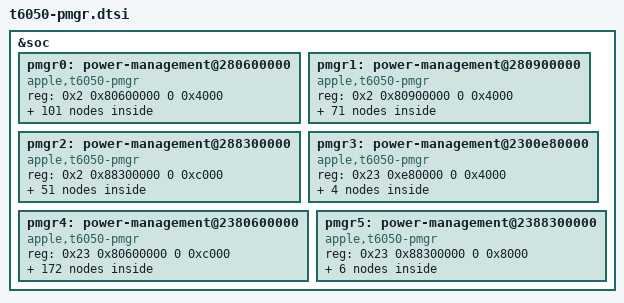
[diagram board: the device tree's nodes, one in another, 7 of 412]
// SPDX-License-Identifier: GPL-2.0+ OR MIT
/*
 * PMGR power domains for the Apple T6050 "M5 Pro" SoC
 *
 * GENERATED from the on-device ADT by scripts/adt2pmgr.py — do not edit
 * by hand; regenerate when the ADT changes (macOS updates can revise it).
 *
 * Copyright The Asahi Linux Contributors / omarchy-m5 contributors
 */

&soc {
	pmgr0: power-management@280600000 {
		compatible = "apple,t6050-pmgr", "apple,t8103-pmgr", "syscon", "simple-mfd";
		#address-cells = <1>;
		#size-cells = <1>;

		reg = <0x2 0x80600000 0 0x4000>;
	};

	pmgr1: power-management@280900000 {
		compatible = "apple,t6050-pmgr", "apple,t8103-pmgr", "syscon", "simple-mfd";
		#address-cells = <1>;
		#size-cells = <1>;

		reg = <0x2 0x80900000 0 0x4000>;
	};

	pmgr2: power-management@288300000 {
		compatible = "apple,t6050-pmgr", "apple,t8103-pmgr", "syscon", "simple-mfd";
		#address-cells = <1>;
		#size-cells = <1>;

		reg = <0x2 0x88300000 0 0xc000>;
	};

	pmgr3: power-management@2300e80000 {
		compatible = "apple,t6050-pmgr", "apple,t8103-pmgr", "syscon", "simple-mfd";
		#address-cells = <1>;
		#size-cells = <1>;

		reg = <0x23 0xe80000 0 0x4000>;
	};

	pmgr4: power-management@2380600000 {
		compatible = "apple,t6050-pmgr", "apple,t8103-pmgr", "syscon", "simple-mfd";
		#address-cells = <1>;
		#size-cells = <1>;

		reg = <0x23 0x80600000 0 0xc000>;
	};

	pmgr5: power-management@2388300000 {
		compatible = "apple,t6050-pmgr", "apple,t8103-pmgr", "syscon", "simple-mfd";
		#address-cells = <1>;
		#size-cells = <1>;

		reg = <0x23 0x88300000 0 0x8000>;
	};

};

&pmgr0 {

	ps_mcpu0_0: power-controller@0 {
		compatible = "apple,t6050-pmgr-pwrstate", "apple,t8103-pmgr-pwrstate";
		reg = <0x0 4>;
		#power-domain-cells = <0>;
		#reset-cells = <0>;
		label = "mcpu0_0";
	};

	ps_mcpu0_1: power-controller@8 {
		compatible = "apple,t6050-pmgr-pwrstate", "apple,t8103-pmgr-pwrstate";
		reg = <0x8 4>;
		#power-domain-cells = <0>;
		#reset-cells = <0>;
		label = "mcpu0_1";
	};

	ps_mcpu0_2: power-controller@10 {
		compatible = "apple,t6050-pmgr-pwrstate", "apple,t8103-pmgr-pwrstate";
		reg = <0x10 4>;
		#power-domain-cells = <0>;
		#reset-cells = <0>;
		label = "mcpu0_2";
	};

	ps_mcpu0_3: power-controller@18 {
		compatible = "apple,t6050-pmgr-pwrstate", "apple,t8103-pmgr-pwrstate";
		reg = <0x18 4>;
		#power-domain-cells = <0>;
		#reset-cells = <0>;
		label = "mcpu0_3";
	};

	ps_mcpu0_4: power-controller@20 {
		compatible = "apple,t6050-pmgr-pwrstate", "apple,t8103-pmgr-pwrstate";
		reg = <0x20 4>;
		#power-domain-cells = <0>;
		#reset-cells = <0>;
		label = "mcpu0_4";
	};

	ps_mcpu0_5: power-controller@28 {
		compatible = "apple,t6050-pmgr-pwrstate", "apple,t8103-pmgr-pwrstate";
		reg = <0x28 4>;
		#power-domain-cells = <0>;
		#reset-cells = <0>;
		label = "mcpu0_5";
	};

	ps_mcpu1_0: power-controller@30 {
		compatible = "apple,t6050-pmgr-pwrstate", "apple,t8103-pmgr-pwrstate";
		reg = <0x30 4>;
		#power-domain-cells = <0>;
		#reset-cells = <0>;
		label = "mcpu1_0";
	};

	ps_mcpu1_1: power-controller@38 {
		compatible = "apple,t6050-pmgr-pwrstate", "apple,t8103-pmgr-pwrstate";
		reg = <0x38 4>;
		#power-domain-cells = <0>;
		#reset-cells = <0>;
		label = "mcpu1_1";
	};

	ps_mcpu1_2: power-controller@40 {
		compatible = "apple,t6050-pmgr-pwrstate", "apple,t8103-pmgr-pwrstate";
		reg = <0x40 4>;
		#power-domain-cells = <0>;
		#reset-cells = <0>;
		label = "mcpu1_2";
	};

	ps_mcpu1_3: power-controller@48 {
		compatible = "apple,t6050-pmgr-pwrstate", "apple,t8103-pmgr-pwrstate";
		reg = <0x48 4>;
		#power-domain-cells = <0>;
		#reset-cells = <0>;
		label = "mcpu1_3";
	};

	ps_mcpu1_4: power-controller@50 {
		compatible = "apple,t6050-pmgr-pwrstate", "apple,t8103-pmgr-pwrstate";
		reg = <0x50 4>;
		#power-domain-cells = <0>;
		#reset-cells = <0>;
		label = "mcpu1_4";
	};

	ps_mcpu1_5: power-controller@58 {
		compatible = "apple,t6050-pmgr-pwrstate", "apple,t8103-pmgr-pwrstate";
		reg = <0x58 4>;
		#power-domain-cells = <0>;
		#reset-cells = <0>;
		label = "mcpu1_5";
	};

	ps_pcpu_0: power-controller@60 {
		compatible = "apple,t6050-pmgr-pwrstate", "apple,t8103-pmgr-pwrstate";
		reg = <0x60 4>;
		#power-domain-cells = <0>;
		#reset-cells = <0>;
		label = "pcpu_0";
	};

	ps_pcpu_1: power-controller@68 {
		compatible = "apple,t6050-pmgr-pwrstate", "apple,t8103-pmgr-pwrstate";
		reg = <0x68 4>;
		#power-domain-cells = <0>;
		#reset-cells = <0>;
		label = "pcpu_1";
	};

	ps_pcpu_2: power-controller@70 {
		compatible = "apple,t6050-pmgr-pwrstate", "apple,t8103-pmgr-pwrstate";
		reg = <0x70 4>;
		#power-domain-cells = <0>;
		#reset-cells = <0>;
		label = "pcpu_2";
	};

	ps_pcpu_3: power-controller@78 {
		compatible = "apple,t6050-pmgr-pwrstate", "apple,t8103-pmgr-pwrstate";
		reg = <0x78 4>;
		#power-domain-cells = <0>;
		#reset-cells = <0>;
		label = "pcpu_3";
	};

	ps_pcpu_4: power-controller@80 {
		compatible = "apple,t6050-pmgr-pwrstate", "apple,t8103-pmgr-pwrstate";
		reg = <0x80 4>;
		#power-domain-cells = <0>;
		#reset-cells = <0>;
		label = "pcpu_4";
	};

	ps_pcpu_5: power-controller@88 {
		compatible = "apple,t6050-pmgr-pwrstate", "apple,t8103-pmgr-pwrstate";
		reg = <0x88 4>;
		#power-domain-cells = <0>;
		#reset-cells = <0>;
		label = "pcpu_5";
	};

	ps_pms: power-controller@100 {
		compatible = "apple,t6050-pmgr-pwrstate", "apple,t8103-pmgr-pwrstate";
		reg = <0x100 4>;
		#power-domain-cells = <0>;
		#reset-cells = <0>;
		label = "pms";
		apple,always-on;
	};

	ps_aic: power-controller@108 {
		compatible = "apple,t6050-pmgr-pwrstate", "apple,t8103-pmgr-pwrstate";
		reg = <0x108 4>;
		#power-domain-cells = <0>;
		#reset-cells = <0>;
		label = "aic";
		power-domains = <&ps_pms>;
	};

	ps_pmc: power-controller@110 {
		compatible = "apple,t6050-pmgr-pwrstate", "apple,t8103-pmgr-pwrstate";
		reg = <0x110 4>;
		#power-domain-cells = <0>;
		#reset-cells = <0>;
		label = "pmc";
		apple,always-on;
		power-domains = <&ps_pms>;
	};

	ps_pms_c1ppt: power-controller@118 {
		compatible = "apple,t6050-pmgr-pwrstate", "apple,t8103-pmgr-pwrstate";
		reg = <0x118 4>;
		#power-domain-cells = <0>;
		#reset-cells = <0>;
		label = "pms_c1ppt";
		apple,always-on;
		power-domains = <&ps_pms>;
	};

	ps_soc_dpe: power-controller@120 {
		compatible = "apple,t6050-pmgr-pwrstate", "apple,t8103-pmgr-pwrstate";
		reg = <0x120 4>;
		#power-domain-cells = <0>;
		#reset-cells = <0>;
		label = "soc_dpe";
		apple,always-on;
		power-domains = <&ps_pms>;
	};

	ps_pmp: power-controller@128 {
		compatible = "apple,t6050-pmgr-pwrstate", "apple,t8103-pmgr-pwrstate";
		reg = <0x128 4>;
		#power-domain-cells = <0>;
		#reset-cells = <0>;
		label = "pmp";
		apple,always-on;
		power-domains = <&ps_pms>;
	};

	ps_pms_sram: power-controller@130 {
		compatible = "apple,t6050-pmgr-pwrstate", "apple,t8103-pmgr-pwrstate";
		reg = <0x130 4>;
		#power-domain-cells = <0>;
		#reset-cells = <0>;
		label = "pms_sram";
		apple,always-on;
		power-domains = <&ps_pms>;
	};

	ps_pmgr_soc_ocla: power-controller@138 {
		compatible = "apple,t6050-pmgr-pwrstate", "apple,t8103-pmgr-pwrstate";
		reg = <0x138 4>;
		#power-domain-cells = <0>;
		#reset-cells = <0>;
		label = "pmgr_soc_ocla";
	};

	ps_b2b_ctrl_nogate: power-controller@140 {
		compatible = "apple,t6050-pmgr-pwrstate", "apple,t8103-pmgr-pwrstate";
		reg = <0x140 4>;
		#power-domain-cells = <0>;
		#reset-cells = <0>;
		label = "b2b_ctrl_nogate";
		apple,always-on;
	};

	ps_fab0_acc_0: power-controller@148 {
		compatible = "apple,t6050-pmgr-pwrstate", "apple,t8103-pmgr-pwrstate";
		reg = <0x148 4>;
		#power-domain-cells = <0>;
		#reset-cells = <0>;
		label = "fab0_acc_0";
		apple,always-on;
	};

	ps_fab0_acc_1: power-controller@150 {
		compatible = "apple,t6050-pmgr-pwrstate", "apple,t8103-pmgr-pwrstate";
		reg = <0x150 4>;
		#power-domain-cells = <0>;
		#reset-cells = <0>;
		label = "fab0_acc_1";
		apple,always-on;
	};

	ps_fab2_acc: power-controller@158 {
		compatible = "apple,t6050-pmgr-pwrstate", "apple,t8103-pmgr-pwrstate";
		reg = <0x158 4>;
		#power-domain-cells = <0>;
		#reset-cells = <0>;
		label = "fab2_acc";
		apple,always-on;
	};

	ps_fab1_acc: power-controller@160 {
		compatible = "apple,t6050-pmgr-pwrstate", "apple,t8103-pmgr-pwrstate";
		reg = <0x160 4>;
		#power-domain-cells = <0>;
		#reset-cells = <0>;
		label = "fab1_acc";
		apple,always-on;
	};

	ps_b2bc_afc_0: power-controller@168 {
		compatible = "apple,t6050-pmgr-pwrstate", "apple,t8103-pmgr-pwrstate";
		reg = <0x168 4>;
		#power-domain-cells = <0>;
		#reset-cells = <0>;
		label = "b2bc_afc_0";
		apple,always-on;
	};

	ps_b2bc_afc_0_dfx: power-controller@170 {
		compatible = "apple,t6050-pmgr-pwrstate", "apple,t8103-pmgr-pwrstate";
		reg = <0x170 4>;
		#power-domain-cells = <0>;
		#reset-cells = <0>;
		label = "b2bc_afc_0_dfx";
		apple,always-on;
		power-domains = <&ps_b2bc_afc_0>;
	};

	ps_b2bc_afc_1: power-controller@178 {
		compatible = "apple,t6050-pmgr-pwrstate", "apple,t8103-pmgr-pwrstate";
		reg = <0x178 4>;
		#power-domain-cells = <0>;
		#reset-cells = <0>;
		label = "b2bc_afc_1";
		apple,always-on;
	};

	ps_b2bc_afc_1_dfx: power-controller@180 {
		compatible = "apple,t6050-pmgr-pwrstate", "apple,t8103-pmgr-pwrstate";
		reg = <0x180 4>;
		#power-domain-cells = <0>;
		#reset-cells = <0>;
		label = "b2bc_afc_1_dfx";
		apple,always-on;
		power-domains = <&ps_b2bc_afc_1>;
	};

	ps_fab0_afi_0: power-controller@188 {
		compatible = "apple,t6050-pmgr-pwrstate", "apple,t8103-pmgr-pwrstate";
		reg = <0x188 4>;
		#power-domain-cells = <0>;
		#reset-cells = <0>;
		label = "fab0_afi_0";
		apple,always-on;
	};

	ps_fab0_afi_1: power-controller@190 {
		compatible = "apple,t6050-pmgr-pwrstate", "apple,t8103-pmgr-pwrstate";
		reg = <0x190 4>;
		#power-domain-cells = <0>;
		#reset-cells = <0>;
		label = "fab0_afi_1";
		apple,always-on;
	};

	ps_fab0_afi_2: power-controller@198 {
		compatible = "apple,t6050-pmgr-pwrstate", "apple,t8103-pmgr-pwrstate";
		reg = <0x198 4>;
		#power-domain-cells = <0>;
		#reset-cells = <0>;
		label = "fab0_afi_2";
		apple,always-on;
	};

	ps_fab0_afi_3: power-controller@1a0 {
		compatible = "apple,t6050-pmgr-pwrstate", "apple,t8103-pmgr-pwrstate";
		reg = <0x1a0 4>;
		#power-domain-cells = <0>;
		#reset-cells = <0>;
		label = "fab0_afi_3";
		apple,always-on;
	};

	ps_fab_b2bc_afi_0: power-controller@1a8 {
		compatible = "apple,t6050-pmgr-pwrstate", "apple,t8103-pmgr-pwrstate";
		reg = <0x1a8 4>;
		#power-domain-cells = <0>;
		#reset-cells = <0>;
		label = "fab_b2bc_afi_0";
		apple,always-on;
	};

	ps_fab_b2bc_afi_1: power-controller@1b0 {
		compatible = "apple,t6050-pmgr-pwrstate", "apple,t8103-pmgr-pwrstate";
		reg = <0x1b0 4>;
		#power-domain-cells = <0>;
		#reset-cells = <0>;
		label = "fab_b2bc_afi_1";
		apple,always-on;
	};

	ps_b2bc_afi_0: power-controller@1b8 {
		compatible = "apple,t6050-pmgr-pwrstate", "apple,t8103-pmgr-pwrstate";
		reg = <0x1b8 4>;
		#power-domain-cells = <0>;
		#reset-cells = <0>;
		label = "b2bc_afi_0";
		apple,always-on;
	};

	ps_b2bc_afi_0_dfx: power-controller@1c0 {
		compatible = "apple,t6050-pmgr-pwrstate", "apple,t8103-pmgr-pwrstate";
		reg = <0x1c0 4>;
		#power-domain-cells = <0>;
		#reset-cells = <0>;
		label = "b2bc_afi_0_dfx";
		apple,always-on;
		power-domains = <&ps_b2bc_afi_0>;
	};

	ps_b2bc_afi_1: power-controller@1c8 {
		compatible = "apple,t6050-pmgr-pwrstate", "apple,t8103-pmgr-pwrstate";
		reg = <0x1c8 4>;
		#power-domain-cells = <0>;
		#reset-cells = <0>;
		label = "b2bc_afi_1";
		apple,always-on;
	};

	ps_b2bc_afi_1_dfx: power-controller@1d0 {
		compatible = "apple,t6050-pmgr-pwrstate", "apple,t8103-pmgr-pwrstate";
		reg = <0x1d0 4>;
		#power-domain-cells = <0>;
		#reset-cells = <0>;
		label = "b2bc_afi_1_dfx";
		apple,always-on;
		power-domains = <&ps_b2bc_afi_1>;
	};

	ps_fab0_piogw: power-controller@1d8 {
		compatible = "apple,t6050-pmgr-pwrstate", "apple,t8103-pmgr-pwrstate";
		reg = <0x1d8 4>;
		#power-domain-cells = <0>;
		#reset-cells = <0>;
		label = "fab0_piogw";
		apple,always-on;
	};

	ps_fab3_soc: power-controller@1e0 {
		compatible = "apple,t6050-pmgr-pwrstate", "apple,t8103-pmgr-pwrstate";
		reg = <0x1e0 4>;
		#power-domain-cells = <0>;
		#reset-cells = <0>;
		label = "fab3_soc";
		apple,always-on;
		power-domains = <&ps_fab0_piogw>;
	};

	ps_fab4_soc: power-controller@1e8 {
		compatible = "apple,t6050-pmgr-pwrstate", "apple,t8103-pmgr-pwrstate";
		reg = <0x1e8 4>;
		#power-domain-cells = <0>;
		#reset-cells = <0>;
		label = "fab4_soc";
		apple,always-on;
		power-domains = <&ps_fab0_piogw>;
	};

	ps_fab5_soc: power-controller@1f0 {
		compatible = "apple,t6050-pmgr-pwrstate", "apple,t8103-pmgr-pwrstate";
		reg = <0x1f0 4>;
		#power-domain-cells = <0>;
		#reset-cells = <0>;
		label = "fab5_soc";
		apple,always-on;
		power-domains = <&ps_fab0_piogw>;
	};

	ps_sbr: power-controller@1f8 {
		compatible = "apple,t6050-pmgr-pwrstate", "apple,t8103-pmgr-pwrstate";
		reg = <0x1f8 4>;
		#power-domain-cells = <0>;
		#reset-cells = <0>;
		label = "sbr";
		apple,always-on;
		power-domains = <&ps_fab3_soc>;
	};

	ps_dispext0_sys: power-controller@200 {
		compatible = "apple,t6050-pmgr-pwrstate", "apple,t8103-pmgr-pwrstate";
		reg = <0x200 4>;
		#power-domain-cells = <0>;
		#reset-cells = <0>;
		label = "dispext0_sys";
		power-domains = <&ps_fab3_soc>;
	};

	ps_atc0_common: power-controller@208 {
		compatible = "apple,t6050-pmgr-pwrstate", "apple,t8103-pmgr-pwrstate";
		reg = <0x208 4>;
		#power-domain-cells = <0>;
		#reset-cells = <0>;
		label = "atc0_common";
		power-domains = <&ps_fab3_soc>;
	};

	ps_atc1_common: power-controller@210 {
		compatible = "apple,t6050-pmgr-pwrstate", "apple,t8103-pmgr-pwrstate";
		reg = <0x210 4>;
		#power-domain-cells = <0>;
		#reset-cells = <0>;
		label = "atc1_common";
		power-domains = <&ps_fab3_soc>;
	};

	ps_dispext2_sys: power-controller@220 {
		compatible = "apple,t6050-pmgr-pwrstate", "apple,t8103-pmgr-pwrstate";
		reg = <0x220 4>;
		#power-domain-cells = <0>;
		#reset-cells = <0>;
		label = "dispext2_sys";
		power-domains = <&ps_fab4_soc>;
	};

	ps_dispext3_sys: power-controller@228 {
		compatible = "apple,t6050-pmgr-pwrstate", "apple,t8103-pmgr-pwrstate";
		reg = <0x228 4>;
		#power-domain-cells = <0>;
		#reset-cells = <0>;
		label = "dispext3_sys";
		power-domains = <&ps_fab4_soc>;
	};

	ps_dispext1_sys: power-controller@230 {
		compatible = "apple,t6050-pmgr-pwrstate", "apple,t8103-pmgr-pwrstate";
		reg = <0x230 4>;
		#power-domain-cells = <0>;
		#reset-cells = <0>;
		label = "dispext1_sys";
		power-domains = <&ps_fab5_soc>;
	};

	ps_atc2_common: power-controller@238 {
		compatible = "apple,t6050-pmgr-pwrstate", "apple,t8103-pmgr-pwrstate";
		reg = <0x238 4>;
		#power-domain-cells = <0>;
		#reset-cells = <0>;
		label = "atc2_common";
		power-domains = <&ps_fab5_soc>;
	};

	ps_atc3_common: power-controller@240 {
		compatible = "apple,t6050-pmgr-pwrstate", "apple,t8103-pmgr-pwrstate";
		reg = <0x240 4>;
		#power-domain-cells = <0>;
		#reset-cells = <0>;
		label = "atc3_common";
		power-domains = <&ps_fab5_soc>;
	};

	ps_auss: power-controller@248 {
		compatible = "apple,t6050-pmgr-pwrstate", "apple,t8103-pmgr-pwrstate";
		reg = <0x248 4>;
		#power-domain-cells = <0>;
		#reset-cells = <0>;
		label = "auss";
		power-domains = <&ps_fab5_soc>;
	};

	ps_gpio: power-controller@250 {
		compatible = "apple,t6050-pmgr-pwrstate", "apple,t8103-pmgr-pwrstate";
		reg = <0x250 4>;
		#power-domain-cells = <0>;
		#reset-cells = <0>;
		label = "gpio";
		power-domains = <&ps_sbr>;
	};

	ps_msg: power-controller@258 {
		compatible = "apple,t6050-pmgr-pwrstate", "apple,t8103-pmgr-pwrstate";
		reg = <0x258 4>;
		#power-domain-cells = <0>;
		#reset-cells = <0>;
		label = "msg";
		power-domains = <&ps_sbr>;
	};

	ps_ap_tmm: power-controller@260 {
		compatible = "apple,t6050-pmgr-pwrstate", "apple,t8103-pmgr-pwrstate";
		reg = <0x260 4>;
		#power-domain-cells = <0>;
		#reset-cells = <0>;
		label = "ap_tmm";
		power-domains = <&ps_sbr>;
	};

	ps_dispext0_fe: power-controller@268 {
		compatible = "apple,t6050-pmgr-pwrstate", "apple,t8103-pmgr-pwrstate";
		reg = <0x268 4>;
		#power-domain-cells = <0>;
		#reset-cells = <0>;
		label = "dispext0_fe";
		power-domains = <&ps_dispext0_sys>;
	};

	ps_dispext0_adma: power-controller@270 {
		compatible = "apple,t6050-pmgr-pwrstate", "apple,t8103-pmgr-pwrstate";
		reg = <0x270 4>;
		#power-domain-cells = <0>;
		#reset-cells = <0>;
		label = "dispext0_adma";
		power-domains = <&ps_dispext0_sys>;
	};

	ps_dispext0_cpu: power-controller@278 {
		compatible = "apple,t6050-pmgr-pwrstate", "apple,t8103-pmgr-pwrstate";
		reg = <0x278 4>;
		#power-domain-cells = <0>;
		#reset-cells = <0>;
		label = "dispext0_cpu";
		power-domains = <&ps_dispext0_fe>;
	};

	ps_atc0_cio: power-controller@280 {
		compatible = "apple,t6050-pmgr-pwrstate", "apple,t8103-pmgr-pwrstate";
		reg = <0x280 4>;
		#power-domain-cells = <0>;
		#reset-cells = <0>;
		label = "atc0_cio";
		power-domains = <&ps_atc0_common>;
	};

	ps_atc0_pcie: power-controller@288 {
		compatible = "apple,t6050-pmgr-pwrstate", "apple,t8103-pmgr-pwrstate";
		reg = <0x288 4>;
		#power-domain-cells = <0>;
		#reset-cells = <0>;
		label = "atc0_pcie";
		power-domains = <&ps_atc0_common>;
	};

	ps_atc1_cio: power-controller@290 {
		compatible = "apple,t6050-pmgr-pwrstate", "apple,t8103-pmgr-pwrstate";
		reg = <0x290 4>;
		#power-domain-cells = <0>;
		#reset-cells = <0>;
		label = "atc1_cio";
		power-domains = <&ps_atc1_common>;
	};

	ps_atc1_pcie: power-controller@298 {
		compatible = "apple,t6050-pmgr-pwrstate", "apple,t8103-pmgr-pwrstate";
		reg = <0x298 4>;
		#power-domain-cells = <0>;
		#reset-cells = <0>;
		label = "atc1_pcie";
		power-domains = <&ps_atc1_common>;
	};

	ps_dispext2_fe: power-controller@2a0 {
		compatible = "apple,t6050-pmgr-pwrstate", "apple,t8103-pmgr-pwrstate";
		reg = <0x2a0 4>;
		#power-domain-cells = <0>;
		#reset-cells = <0>;
		label = "dispext2_fe";
		power-domains = <&ps_dispext2_sys>;
	};

	ps_dispext2_adma: power-controller@2a8 {
		compatible = "apple,t6050-pmgr-pwrstate", "apple,t8103-pmgr-pwrstate";
		reg = <0x2a8 4>;
		#power-domain-cells = <0>;
		#reset-cells = <0>;
		label = "dispext2_adma";
		power-domains = <&ps_dispext2_sys>;
	};

	ps_dispext2_cpu: power-controller@2b0 {
		compatible = "apple,t6050-pmgr-pwrstate", "apple,t8103-pmgr-pwrstate";
		reg = <0x2b0 4>;
		#power-domain-cells = <0>;
		#reset-cells = <0>;
		label = "dispext2_cpu";
		power-domains = <&ps_dispext2_fe>;
	};

	ps_dispext3_fe: power-controller@2b8 {
		compatible = "apple,t6050-pmgr-pwrstate", "apple,t8103-pmgr-pwrstate";
		reg = <0x2b8 4>;
		#power-domain-cells = <0>;
		#reset-cells = <0>;
		label = "dispext3_fe";
		power-domains = <&ps_dispext3_sys>;
	};

	ps_dispext3_adma: power-controller@2c0 {
		compatible = "apple,t6050-pmgr-pwrstate", "apple,t8103-pmgr-pwrstate";
		reg = <0x2c0 4>;
		#power-domain-cells = <0>;
		#reset-cells = <0>;
		label = "dispext3_adma";
		power-domains = <&ps_dispext3_sys>;
	};

	ps_dispext3_cpu: power-controller@2c8 {
		compatible = "apple,t6050-pmgr-pwrstate", "apple,t8103-pmgr-pwrstate";
		reg = <0x2c8 4>;
		#power-domain-cells = <0>;
		#reset-cells = <0>;
		label = "dispext3_cpu";
		power-domains = <&ps_dispext3_fe>;
	};

	ps_dispext1_fe: power-controller@2d0 {
		compatible = "apple,t6050-pmgr-pwrstate", "apple,t8103-pmgr-pwrstate";
		reg = <0x2d0 4>;
		#power-domain-cells = <0>;
		#reset-cells = <0>;
		label = "dispext1_fe";
		power-domains = <&ps_dispext1_sys>;
	};

	ps_dispext1_adma: power-controller@2d8 {
		compatible = "apple,t6050-pmgr-pwrstate", "apple,t8103-pmgr-pwrstate";
		reg = <0x2d8 4>;
		#power-domain-cells = <0>;
		#reset-cells = <0>;
		label = "dispext1_adma";
		power-domains = <&ps_dispext1_sys>;
	};

	ps_dispext1_cpu: power-controller@2e0 {
		compatible = "apple,t6050-pmgr-pwrstate", "apple,t8103-pmgr-pwrstate";
		reg = <0x2e0 4>;
		#power-domain-cells = <0>;
		#reset-cells = <0>;
		label = "dispext1_cpu";
		power-domains = <&ps_dispext1_fe>;
	};

	ps_atc2_cio: power-controller@2e8 {
		compatible = "apple,t6050-pmgr-pwrstate", "apple,t8103-pmgr-pwrstate";
		reg = <0x2e8 4>;
		#power-domain-cells = <0>;
		#reset-cells = <0>;
		label = "atc2_cio";
		power-domains = <&ps_atc2_common>;
	};

	ps_atc2_pcie: power-controller@2f0 {
		compatible = "apple,t6050-pmgr-pwrstate", "apple,t8103-pmgr-pwrstate";
		reg = <0x2f0 4>;
		#power-domain-cells = <0>;
		#reset-cells = <0>;
		label = "atc2_pcie";
		power-domains = <&ps_atc2_common>;
	};

	ps_atc3_cio: power-controller@2f8 {
		compatible = "apple,t6050-pmgr-pwrstate", "apple,t8103-pmgr-pwrstate";
		reg = <0x2f8 4>;
		#power-domain-cells = <0>;
		#reset-cells = <0>;
		label = "atc3_cio";
		power-domains = <&ps_atc3_common>;
	};

	ps_atc3_pcie: power-controller@300 {
		compatible = "apple,t6050-pmgr-pwrstate", "apple,t8103-pmgr-pwrstate";
		reg = <0x300 4>;
		#power-domain-cells = <0>;
		#reset-cells = <0>;
		label = "atc3_pcie";
		power-domains = <&ps_atc3_common>;
	};

	ps_atc0_cio_pcie: power-controller@338 {
		compatible = "apple,t6050-pmgr-pwrstate", "apple,t8103-pmgr-pwrstate";
		reg = <0x338 4>;
		#power-domain-cells = <0>;
		#reset-cells = <0>;
		label = "atc0_cio_pcie";
		power-domains = <&ps_atc0_cio>;
	};

	ps_atc0_cio_usb: power-controller@340 {
		compatible = "apple,t6050-pmgr-pwrstate", "apple,t8103-pmgr-pwrstate";
		reg = <0x340 4>;
		#power-domain-cells = <0>;
		#reset-cells = <0>;
		label = "atc0_cio_usb";
		power-domains = <&ps_atc0_cio>;
	};

	ps_atc0_cio_auss: power-controller@348 {
		compatible = "apple,t6050-pmgr-pwrstate", "apple,t8103-pmgr-pwrstate";
		reg = <0x348 4>;
		#power-domain-cells = <0>;
		#reset-cells = <0>;
		label = "atc0_cio_auss";
		power-domains = <&ps_atc0_cio>, <&ps_auss>;
	};

	ps_atc1_cio_pcie: power-controller@350 {
		compatible = "apple,t6050-pmgr-pwrstate", "apple,t8103-pmgr-pwrstate";
		reg = <0x350 4>;
		#power-domain-cells = <0>;
		#reset-cells = <0>;
		label = "atc1_cio_pcie";
		power-domains = <&ps_atc1_cio>;
	};

	ps_atc1_cio_usb: power-controller@358 {
		compatible = "apple,t6050-pmgr-pwrstate", "apple,t8103-pmgr-pwrstate";
		reg = <0x358 4>;
		#power-domain-cells = <0>;
		#reset-cells = <0>;
		label = "atc1_cio_usb";
		power-domains = <&ps_atc1_cio>;
	};

	ps_atc1_cio_auss: power-controller@360 {
		compatible = "apple,t6050-pmgr-pwrstate", "apple,t8103-pmgr-pwrstate";
		reg = <0x360 4>;
		#power-domain-cells = <0>;
		#reset-cells = <0>;
		label = "atc1_cio_auss";
		power-domains = <&ps_atc1_cio>, <&ps_auss>;
	};

	ps_atc2_cio_pcie: power-controller@3f8 {
		compatible = "apple,t6050-pmgr-pwrstate", "apple,t8103-pmgr-pwrstate";
		reg = <0x3f8 4>;
		#power-domain-cells = <0>;
		#reset-cells = <0>;
		label = "atc2_cio_pcie";
		power-domains = <&ps_atc2_cio>;
	};

	ps_atc2_cio_usb: power-controller@400 {
		compatible = "apple,t6050-pmgr-pwrstate", "apple,t8103-pmgr-pwrstate";
		reg = <0x400 4>;
		#power-domain-cells = <0>;
		#reset-cells = <0>;
		label = "atc2_cio_usb";
		power-domains = <&ps_atc2_cio>;
	};

	ps_atc2_cio_auss: power-controller@408 {
		compatible = "apple,t6050-pmgr-pwrstate", "apple,t8103-pmgr-pwrstate";
		reg = <0x408 4>;
		#power-domain-cells = <0>;
		#reset-cells = <0>;
		label = "atc2_cio_auss";
		power-domains = <&ps_atc2_cio>, <&ps_auss>;
	};

	ps_atc3_cio_pcie: power-controller@410 {
		compatible = "apple,t6050-pmgr-pwrstate", "apple,t8103-pmgr-pwrstate";
		reg = <0x410 4>;
		#power-domain-cells = <0>;
		#reset-cells = <0>;
		label = "atc3_cio_pcie";
		power-domains = <&ps_atc3_cio>;
	};

	ps_atc3_cio_usb: power-controller@418 {
		compatible = "apple,t6050-pmgr-pwrstate", "apple,t8103-pmgr-pwrstate";
		reg = <0x418 4>;
		#power-domain-cells = <0>;
		#reset-cells = <0>;
		label = "atc3_cio_usb";
		power-domains = <&ps_atc3_cio>;
	};

	ps_atc3_cio_auss: power-controller@420 {
		compatible = "apple,t6050-pmgr-pwrstate", "apple,t8103-pmgr-pwrstate";
		reg = <0x420 4>;
		#power-domain-cells = <0>;
		#reset-cells = <0>;
		label = "atc3_cio_auss";
		power-domains = <&ps_atc3_cio>, <&ps_auss>;
	};

	ps_fab0_afigw: power-controller@448 {
		compatible = "apple,t6050-pmgr-pwrstate", "apple,t8103-pmgr-pwrstate";
		reg = <0x448 4>;
		#power-domain-cells = <0>;
		#reset-cells = <0>;
		label = "fab0_afigw";
		apple,always-on;
	};

	ps_fppt: power-controller@450 {
		compatible = "apple,t6050-pmgr-pwrstate", "apple,t8103-pmgr-pwrstate";
		reg = <0x450 4>;
		#power-domain-cells = <0>;
		#reset-cells = <0>;
		label = "fppt";
		power-domains = <&ps_fab0_afigw>;
	};

	ps_b2bc_dft: power-controller@458 {
		compatible = "apple,t6050-pmgr-pwrstate", "apple,t8103-pmgr-pwrstate";
		reg = <0x458 4>;
		#power-domain-cells = <0>;
		#reset-cells = <0>;
		label = "b2bc_dft";
	};

	ps_b2bc_cntl_dfx: power-controller@460 {
		compatible = "apple,t6050-pmgr-pwrstate", "apple,t8103-pmgr-pwrstate";
		reg = <0x460 4>;
		#power-domain-cells = <0>;
		#reset-cells = <0>;
		label = "b2bc_cntl_dfx";
	};

	ps_b2bc_dbg_0: power-controller@468 {
		compatible = "apple,t6050-pmgr-pwrstate", "apple,t8103-pmgr-pwrstate";
		reg = <0x468 4>;
		#power-domain-cells = <0>;
		#reset-cells = <0>;
		label = "b2bc_dbg_0";
	};

	ps_b2bc_dbg_1: power-controller@470 {
		compatible = "apple,t6050-pmgr-pwrstate", "apple,t8103-pmgr-pwrstate";
		reg = <0x470 4>;
		#power-domain-cells = <0>;
		#reset-cells = <0>;
		label = "b2bc_dbg_1";
	};

	ps_b2bc_dbg_2: power-controller@478 {
		compatible = "apple,t6050-pmgr-pwrstate", "apple,t8103-pmgr-pwrstate";
		reg = <0x478 4>;
		#power-domain-cells = <0>;
		#reset-cells = <0>;
		label = "b2bc_dbg_2";
	};
};

&pmgr1 {

	ps_ispsens0: power-controller@100 {
		compatible = "apple,t6050-pmgr-pwrstate", "apple,t8103-pmgr-pwrstate";
		reg = <0x100 4>;
		#power-domain-cells = <0>;
		#reset-cells = <0>;
		label = "ispsens0";
	};

	ps_global_aux_hpd_0: power-controller@108 {
		compatible = "apple,t6050-pmgr-pwrstate", "apple,t8103-pmgr-pwrstate";
		reg = <0x108 4>;
		#power-domain-cells = <0>;
		#reset-cells = <0>;
		label = "global_aux_hpd_0";
	};

	ps_global_aux_hpd_1: power-controller@110 {
		compatible = "apple,t6050-pmgr-pwrstate", "apple,t8103-pmgr-pwrstate";
		reg = <0x110 4>;
		#power-domain-cells = <0>;
		#reset-cells = <0>;
		label = "global_aux_hpd_1";
	};

	ps_apcie_gp: power-controller@118 {
		compatible = "apple,t6050-pmgr-pwrstate", "apple,t8103-pmgr-pwrstate";
		reg = <0x118 4>;
		#power-domain-cells = <0>;
		#reset-cells = <0>;
		label = "apcie_gp";
	};

	ps_apcie_ge: power-controller@120 {
		compatible = "apple,t6050-pmgr-pwrstate", "apple,t8103-pmgr-pwrstate";
		reg = <0x120 4>;
		#power-domain-cells = <0>;
		#reset-cells = <0>;
		label = "apcie_ge";
	};

	ps_apcie_st0: power-controller@128 {
		compatible = "apple,t6050-pmgr-pwrstate", "apple,t8103-pmgr-pwrstate";
		reg = <0x128 4>;
		#power-domain-cells = <0>;
		#reset-cells = <0>;
		label = "apcie_st0";
	};

	ps_apcie_st1: power-controller@130 {
		compatible = "apple,t6050-pmgr-pwrstate", "apple,t8103-pmgr-pwrstate";
		reg = <0x130 4>;
		#power-domain-cells = <0>;
		#reset-cells = <0>;
		label = "apcie_st1";
	};

	ps_fab6_soc: power-controller@138 {
		compatible = "apple,t6050-pmgr-pwrstate", "apple,t8103-pmgr-pwrstate";
		reg = <0x138 4>;
		#power-domain-cells = <0>;
		#reset-cells = <0>;
		label = "fab6_soc";
		apple,always-on;
		power-domains = <&ps_fab0_piogw>;
	};

	ps_ans: power-controller@140 {
		compatible = "apple,t6050-pmgr-pwrstate", "apple,t8103-pmgr-pwrstate";
		reg = <0x140 4>;
		#power-domain-cells = <0>;
		#reset-cells = <0>;
		label = "ans";
		power-domains = <&ps_fab6_soc>;
	};

	ps_apcie_sys_gp: power-controller@148 {
		compatible = "apple,t6050-pmgr-pwrstate", "apple,t8103-pmgr-pwrstate";
		reg = <0x148 4>;
		#power-domain-cells = <0>;
		#reset-cells = <0>;
		label = "apcie_sys_gp";
		power-domains = <&ps_apcie_gp>, <&ps_fab6_soc>;
	};

	ps_apcie_sys_st0: power-controller@150 {
		compatible = "apple,t6050-pmgr-pwrstate", "apple,t8103-pmgr-pwrstate";
		reg = <0x150 4>;
		#power-domain-cells = <0>;
		#reset-cells = <0>;
		label = "apcie_sys_st0";
		power-domains = <&ps_apcie_st0>, <&ps_ans>;
	};

	ps_apcie_sys_st1: power-controller@158 {
		compatible = "apple,t6050-pmgr-pwrstate", "apple,t8103-pmgr-pwrstate";
		reg = <0x158 4>;
		#power-domain-cells = <0>;
		#reset-cells = <0>;
		label = "apcie_sys_st1";
		power-domains = <&ps_apcie_st1>, <&ps_ans>;
	};

	ps_apcie_sys_gp_oc: power-controller@160 {
		compatible = "apple,t6050-pmgr-pwrstate", "apple,t8103-pmgr-pwrstate";
		reg = <0x160 4>;
		#power-domain-cells = <0>;
		#reset-cells = <0>;
		label = "apcie_sys_gp_oc";
		power-domains = <&ps_apcie_sys_gp>;
	};

	ps_apcie_sys_st0_o: power-controller@168 {
		compatible = "apple,t6050-pmgr-pwrstate", "apple,t8103-pmgr-pwrstate";
		reg = <0x168 4>;
		#power-domain-cells = <0>;
		#reset-cells = <0>;
		label = "apcie_sys_st0_o";
		power-domains = <&ps_apcie_sys_st0>;
	};

	ps_apcie_sys_st1_o: power-controller@170 {
		compatible = "apple,t6050-pmgr-pwrstate", "apple,t8103-pmgr-pwrstate";
		reg = <0x170 4>;
		#power-domain-cells = <0>;
		#reset-cells = <0>;
		label = "apcie_sys_st1_o";
		power-domains = <&ps_apcie_sys_st1>;
	};

	ps_fab7_soc: power-controller@178 {
		compatible = "apple,t6050-pmgr-pwrstate", "apple,t8103-pmgr-pwrstate";
		reg = <0x178 4>;
		#power-domain-cells = <0>;
		#reset-cells = <0>;
		label = "fab7_soc";
		apple,always-on;
		power-domains = <&ps_fab0_piogw>;
	};

	ps_disp_sys: power-controller@180 {
		compatible = "apple,t6050-pmgr-pwrstate", "apple,t8103-pmgr-pwrstate";
		reg = <0x180 4>;
		#power-domain-cells = <0>;
		#reset-cells = <0>;
		label = "disp_sys";
		power-domains = <&ps_fab7_soc>;
	};

	ps_apcie_sys_ge: power-controller@188 {
		compatible = "apple,t6050-pmgr-pwrstate", "apple,t8103-pmgr-pwrstate";
		reg = <0x188 4>;
		#power-domain-cells = <0>;
		#reset-cells = <0>;
		label = "apcie_sys_ge";
		power-domains = <&ps_apcie_ge>, <&ps_fab6_soc>;
	};

	ps_scodec: power-controller@190 {
		compatible = "apple,t6050-pmgr-pwrstate", "apple,t8103-pmgr-pwrstate";
		reg = <0x190 4>;
		#power-domain-cells = <0>;
		#reset-cells = <0>;
		label = "scodec";
		power-domains = <&ps_fab7_soc>;
	};

	ps_disp_fe: power-controller@198 {
		compatible = "apple,t6050-pmgr-pwrstate", "apple,t8103-pmgr-pwrstate";
		reg = <0x198 4>;
		#power-domain-cells = <0>;
		#reset-cells = <0>;
		label = "disp_fe";
		power-domains = <&ps_disp_sys>;
	};

	ps_disp_adma: power-controller@1a0 {
		compatible = "apple,t6050-pmgr-pwrstate", "apple,t8103-pmgr-pwrstate";
		reg = <0x1a0 4>;
		#power-domain-cells = <0>;
		#reset-cells = <0>;
		label = "disp_adma";
		power-domains = <&ps_disp_sys>;
	};

	ps_disp_cpu: power-controller@1a8 {
		compatible = "apple,t6050-pmgr-pwrstate", "apple,t8103-pmgr-pwrstate";
		reg = <0x1a8 4>;
		#power-domain-cells = <0>;
		#reset-cells = <0>;
		label = "disp_cpu";
		power-domains = <&ps_disp_fe>;
	};

	ps_apcie_phy_sw: power-controller@1b0 {
		compatible = "apple,t6050-pmgr-pwrstate", "apple,t8103-pmgr-pwrstate";
		reg = <0x1b0 4>;
		#power-domain-cells = <0>;
		#reset-cells = <0>;
		label = "apcie_phy_sw";
		power-domains = <&ps_apcie_sys_gp>, <&ps_apcie_sys_ge>;
	};

	ps_apcie_sys_ge_ol: power-controller@1b8 {
		compatible = "apple,t6050-pmgr-pwrstate", "apple,t8103-pmgr-pwrstate";
		reg = <0x1b8 4>;
		#power-domain-cells = <0>;
		#reset-cells = <0>;
		label = "apcie_sys_ge_ol";
		power-domains = <&ps_apcie_sys_ge>;
	};

	ps_scodec_streaming: power-controller@1c0 {
		compatible = "apple,t6050-pmgr-pwrstate", "apple,t8103-pmgr-pwrstate";
		reg = <0x1c0 4>;
		#power-domain-cells = <0>;
		#reset-cells = <0>;
		label = "scodec_streaming";
		power-domains = <&ps_scodec>;
	};

	ps_aphy_st0_aus5_a: power-controller@240 {
		compatible = "apple,t6050-pmgr-pwrstate", "apple,t8103-pmgr-pwrstate";
		reg = <0x240 4>;
		#power-domain-cells = <0>;
		#reset-cells = <0>;
		label = "aphy_st0_aus5_a";
		power-domains = <&ps_apcie_phy_sw>;
	};

	ps_aphy_st1_aus5_a: power-controller@248 {
		compatible = "apple,t6050-pmgr-pwrstate", "apple,t8103-pmgr-pwrstate";
		reg = <0x248 4>;
		#power-domain-cells = <0>;
		#reset-cells = <0>;
		label = "aphy_st1_aus5_a";
		power-domains = <&ps_apcie_phy_sw>;
	};

	ps_aphy_ge_aus5_a: power-controller@250 {
		compatible = "apple,t6050-pmgr-pwrstate", "apple,t8103-pmgr-pwrstate";
		reg = <0x250 4>;
		#power-domain-cells = <0>;
		#reset-cells = <0>;
		label = "aphy_ge_aus5_a";
		power-domains = <&ps_apcie_phy_sw>;
	};

	ps_aphy_gp_aus5_a: power-controller@258 {
		compatible = "apple,t6050-pmgr-pwrstate", "apple,t8103-pmgr-pwrstate";
		reg = <0x258 4>;
		#power-domain-cells = <0>;
		#reset-cells = <0>;
		label = "aphy_gp_aus5_a";
		power-domains = <&ps_apcie_phy_sw>;
	};

	ps_aphy_st0_aus5: power-controller@268 {
		compatible = "apple,t6050-pmgr-pwrstate", "apple,t8103-pmgr-pwrstate";
		reg = <0x268 4>;
		#power-domain-cells = <0>;
		#reset-cells = <0>;
		label = "aphy_st0_aus5";
		power-domains = <&ps_aphy_st0_aus5_a>;
	};

	ps_aphy_st1_aus5: power-controller@270 {
		compatible = "apple,t6050-pmgr-pwrstate", "apple,t8103-pmgr-pwrstate";
		reg = <0x270 4>;
		#power-domain-cells = <0>;
		#reset-cells = <0>;
		label = "aphy_st1_aus5";
		power-domains = <&ps_aphy_st1_aus5_a>;
	};

	ps_aphy_ge_aus5: power-controller@278 {
		compatible = "apple,t6050-pmgr-pwrstate", "apple,t8103-pmgr-pwrstate";
		reg = <0x278 4>;
		#power-domain-cells = <0>;
		#reset-cells = <0>;
		label = "aphy_ge_aus5";
		power-domains = <&ps_aphy_ge_aus5_a>;
	};

	ps_aphy_gp_aus5: power-controller@280 {
		compatible = "apple,t6050-pmgr-pwrstate", "apple,t8103-pmgr-pwrstate";
		reg = <0x280 4>;
		#power-domain-cells = <0>;
		#reset-cells = <0>;
		label = "aphy_gp_aus5";
		power-domains = <&ps_aphy_gp_aus5_a>;
	};

	ps_fab8_soc: power-controller@288 {
		compatible = "apple,t6050-pmgr-pwrstate", "apple,t8103-pmgr-pwrstate";
		reg = <0x288 4>;
		#power-domain-cells = <0>;
		#reset-cells = <0>;
		label = "fab8_soc";
		apple,always-on;
		power-domains = <&ps_fab0_piogw>;
	};

	ps_sio: power-controller@290 {
		compatible = "apple,t6050-pmgr-pwrstate", "apple,t8103-pmgr-pwrstate";
		reg = <0x290 4>;
		#power-domain-cells = <0>;
		#reset-cells = <0>;
		label = "sio";
		apple,always-on;
		power-domains = <&ps_fab8_soc>;
	};

	ps_sep: power-controller@298 {
		compatible = "apple,t6050-pmgr-pwrstate", "apple,t8103-pmgr-pwrstate";
		reg = <0x298 4>;
		#power-domain-cells = <0>;
		#reset-cells = <0>;
		label = "sep";
		apple,always-on;
		power-domains = <&ps_fab8_soc>;
	};

	ps_sio_cpu: power-controller@2a0 {
		compatible = "apple,t6050-pmgr-pwrstate", "apple,t8103-pmgr-pwrstate";
		reg = <0x2a0 4>;
		#power-domain-cells = <0>;
		#reset-cells = <0>;
		label = "sio_cpu";
		apple,always-on;
		power-domains = <&ps_sio>;
	};

	ps_fpwm0: power-controller@2a8 {
		compatible = "apple,t6050-pmgr-pwrstate", "apple,t8103-pmgr-pwrstate";
		reg = <0x2a8 4>;
		#power-domain-cells = <0>;
		#reset-cells = <0>;
		label = "fpwm0";
		power-domains = <&ps_sio>;
	};

	ps_fpwm2: power-controller@2b8 {
		compatible = "apple,t6050-pmgr-pwrstate", "apple,t8103-pmgr-pwrstate";
		reg = <0x2b8 4>;
		#power-domain-cells = <0>;
		#reset-cells = <0>;
		label = "fpwm2";
		power-domains = <&ps_sio>;
	};

	ps_i2c0: power-controller@2c0 {
		compatible = "apple,t6050-pmgr-pwrstate", "apple,t8103-pmgr-pwrstate";
		reg = <0x2c0 4>;
		#power-domain-cells = <0>;
		#reset-cells = <0>;
		label = "i2c0";
		power-domains = <&ps_sio>;
	};

	ps_i2c1: power-controller@2c8 {
		compatible = "apple,t6050-pmgr-pwrstate", "apple,t8103-pmgr-pwrstate";
		reg = <0x2c8 4>;
		#power-domain-cells = <0>;
		#reset-cells = <0>;
		label = "i2c1";
		power-domains = <&ps_sio>;
	};

	ps_i2c2: power-controller@2d0 {
		compatible = "apple,t6050-pmgr-pwrstate", "apple,t8103-pmgr-pwrstate";
		reg = <0x2d0 4>;
		#power-domain-cells = <0>;
		#reset-cells = <0>;
		label = "i2c2";
		power-domains = <&ps_sio>;
	};

	ps_i2c3: power-controller@2d8 {
		compatible = "apple,t6050-pmgr-pwrstate", "apple,t8103-pmgr-pwrstate";
		reg = <0x2d8 4>;
		#power-domain-cells = <0>;
		#reset-cells = <0>;
		label = "i2c3";
		power-domains = <&ps_sio>;
	};

	ps_i2c4: power-controller@2e0 {
		compatible = "apple,t6050-pmgr-pwrstate", "apple,t8103-pmgr-pwrstate";
		reg = <0x2e0 4>;
		#power-domain-cells = <0>;
		#reset-cells = <0>;
		label = "i2c4";
		power-domains = <&ps_sio>;
	};

	ps_i2c5: power-controller@2e8 {
		compatible = "apple,t6050-pmgr-pwrstate", "apple,t8103-pmgr-pwrstate";
		reg = <0x2e8 4>;
		#power-domain-cells = <0>;
		#reset-cells = <0>;
		label = "i2c5";
		power-domains = <&ps_sio>;
	};

	ps_i2c6: power-controller@2f0 {
		compatible = "apple,t6050-pmgr-pwrstate", "apple,t8103-pmgr-pwrstate";
		reg = <0x2f0 4>;
		#power-domain-cells = <0>;
		#reset-cells = <0>;
		label = "i2c6";
		power-domains = <&ps_sio>;
	};

	ps_i2c7: power-controller@2f8 {
		compatible = "apple,t6050-pmgr-pwrstate", "apple,t8103-pmgr-pwrstate";
		reg = <0x2f8 4>;
		#power-domain-cells = <0>;
		#reset-cells = <0>;
		label = "i2c7";
		power-domains = <&ps_sio>;
	};

	ps_i2c8: power-controller@300 {
		compatible = "apple,t6050-pmgr-pwrstate", "apple,t8103-pmgr-pwrstate";
		reg = <0x300 4>;
		#power-domain-cells = <0>;
		#reset-cells = <0>;
		label = "i2c8";
		power-domains = <&ps_sio>;
	};

	ps_spi_p: power-controller@308 {
		compatible = "apple,t6050-pmgr-pwrstate", "apple,t8103-pmgr-pwrstate";
		reg = <0x308 4>;
		#power-domain-cells = <0>;
		#reset-cells = <0>;
		label = "spi_p";
		power-domains = <&ps_sio>;
	};

	ps_uart_p: power-controller@310 {
		compatible = "apple,t6050-pmgr-pwrstate", "apple,t8103-pmgr-pwrstate";
		reg = <0x310 4>;
		#power-domain-cells = <0>;
		#reset-cells = <0>;
		label = "uart_p";
		power-domains = <&ps_sio>;
	};

	ps_aes: power-controller@318 {
		compatible = "apple,t6050-pmgr-pwrstate", "apple,t8103-pmgr-pwrstate";
		reg = <0x318 4>;
		#power-domain-cells = <0>;
		#reset-cells = <0>;
		label = "aes";
		power-domains = <&ps_sio>;
	};

	ps_spi0: power-controller@320 {
		compatible = "apple,t6050-pmgr-pwrstate", "apple,t8103-pmgr-pwrstate";
		reg = <0x320 4>;
		#power-domain-cells = <0>;
		#reset-cells = <0>;
		label = "spi0";
		power-domains = <&ps_spi_p>;
	};

	ps_spi1: power-controller@328 {
		compatible = "apple,t6050-pmgr-pwrstate", "apple,t8103-pmgr-pwrstate";
		reg = <0x328 4>;
		#power-domain-cells = <0>;
		#reset-cells = <0>;
		label = "spi1";
		power-domains = <&ps_spi_p>;
	};

	ps_spi2: power-controller@330 {
		compatible = "apple,t6050-pmgr-pwrstate", "apple,t8103-pmgr-pwrstate";
		reg = <0x330 4>;
		#power-domain-cells = <0>;
		#reset-cells = <0>;
		label = "spi2";
		power-domains = <&ps_spi_p>;
	};

	ps_spi3: power-controller@338 {
		compatible = "apple,t6050-pmgr-pwrstate", "apple,t8103-pmgr-pwrstate";
		reg = <0x338 4>;
		#power-domain-cells = <0>;
		#reset-cells = <0>;
		label = "spi3";
		power-domains = <&ps_spi_p>;
	};

	ps_spi4: power-controller@340 {
		compatible = "apple,t6050-pmgr-pwrstate", "apple,t8103-pmgr-pwrstate";
		reg = <0x340 4>;
		#power-domain-cells = <0>;
		#reset-cells = <0>;
		label = "spi4";
		power-domains = <&ps_spi_p>;
	};

	ps_spi5: power-controller@348 {
		compatible = "apple,t6050-pmgr-pwrstate", "apple,t8103-pmgr-pwrstate";
		reg = <0x348 4>;
		#power-domain-cells = <0>;
		#reset-cells = <0>;
		label = "spi5";
		power-domains = <&ps_spi_p>;
	};

	ps_qspi: power-controller@350 {
		compatible = "apple,t6050-pmgr-pwrstate", "apple,t8103-pmgr-pwrstate";
		reg = <0x350 4>;
		#power-domain-cells = <0>;
		#reset-cells = <0>;
		label = "qspi";
		power-domains = <&ps_spi_p>;
	};

	ps_uart_n: power-controller@358 {
		compatible = "apple,t6050-pmgr-pwrstate", "apple,t8103-pmgr-pwrstate";
		reg = <0x358 4>;
		#power-domain-cells = <0>;
		#reset-cells = <0>;
		label = "uart_n";
		power-domains = <&ps_uart_p>;
	};

	ps_uart0: power-controller@360 {
		compatible = "apple,t6050-pmgr-pwrstate", "apple,t8103-pmgr-pwrstate";
		reg = <0x360 4>;
		#power-domain-cells = <0>;
		#reset-cells = <0>;
		label = "uart0";
		power-domains = <&ps_uart_p>;
	};

	ps_uart1: power-controller@368 {
		compatible = "apple,t6050-pmgr-pwrstate", "apple,t8103-pmgr-pwrstate";
		reg = <0x368 4>;
		#power-domain-cells = <0>;
		#reset-cells = <0>;
		label = "uart1";
		power-domains = <&ps_uart_p>;
	};

	ps_uart2: power-controller@370 {
		compatible = "apple,t6050-pmgr-pwrstate", "apple,t8103-pmgr-pwrstate";
		reg = <0x370 4>;
		#power-domain-cells = <0>;
		#reset-cells = <0>;
		label = "uart2";
		power-domains = <&ps_uart_p>;
	};

	ps_uart3: power-controller@378 {
		compatible = "apple,t6050-pmgr-pwrstate", "apple,t8103-pmgr-pwrstate";
		reg = <0x378 4>;
		#power-domain-cells = <0>;
		#reset-cells = <0>;
		label = "uart3";
		power-domains = <&ps_uart_p>;
	};

	ps_uart4: power-controller@380 {
		compatible = "apple,t6050-pmgr-pwrstate", "apple,t8103-pmgr-pwrstate";
		reg = <0x380 4>;
		#power-domain-cells = <0>;
		#reset-cells = <0>;
		label = "uart4";
		power-domains = <&ps_uart_p>;
	};

	ps_uart5: power-controller@388 {
		compatible = "apple,t6050-pmgr-pwrstate", "apple,t8103-pmgr-pwrstate";
		reg = <0x388 4>;
		#power-domain-cells = <0>;
		#reset-cells = <0>;
		label = "uart5";
		power-domains = <&ps_uart_p>;
	};

	ps_uart6: power-controller@390 {
		compatible = "apple,t6050-pmgr-pwrstate", "apple,t8103-pmgr-pwrstate";
		reg = <0x390 4>;
		#power-domain-cells = <0>;
		#reset-cells = <0>;
		label = "uart6";
		power-domains = <&ps_uart_p>;
	};

	ps_fab9_soc: power-controller@398 {
		compatible = "apple,t6050-pmgr-pwrstate", "apple,t8103-pmgr-pwrstate";
		reg = <0x398 4>;
		#power-domain-cells = <0>;
		#reset-cells = <0>;
		label = "fab9_soc";
		apple,always-on;
		power-domains = <&ps_fab0_piogw>;
	};

	ps_isp_sys: power-controller@3a0 {
		compatible = "apple,t6050-pmgr-pwrstate", "apple,t8103-pmgr-pwrstate";
		reg = <0x3a0 4>;
		#power-domain-cells = <0>;
		#reset-cells = <0>;
		label = "isp_sys";
		power-domains = <&ps_fab9_soc>;
	};

	ps_ane_mpm: power-controller@3c0 {
		compatible = "apple,t6050-pmgr-pwrstate", "apple,t8103-pmgr-pwrstate";
		reg = <0x3c0 4>;
		#power-domain-cells = <0>;
		#reset-cells = <0>;
		label = "ane_mpm";
	};

	ps_ane_cpu: power-controller@3c8 {
		compatible = "apple,t6050-pmgr-pwrstate", "apple,t8103-pmgr-pwrstate";
		reg = <0x3c8 4>;
		#power-domain-cells = <0>;
		#reset-cells = <0>;
		label = "ane_cpu";
	};

	ps_ane_tdbase: power-controller@3d0 {
		compatible = "apple,t6050-pmgr-pwrstate", "apple,t8103-pmgr-pwrstate";
		reg = <0x3d0 4>;
		#power-domain-cells = <0>;
		#reset-cells = <0>;
		label = "ane_tdbase";
	};
};

&pmgr2 {

	ps_debug_gated: power-controller@58 {
		compatible = "apple,t6050-pmgr-pwrstate", "apple,t8103-pmgr-pwrstate";
		reg = <0x58 4>;
		#power-domain-cells = <0>;
		#reset-cells = <0>;
		label = "debug_gated";
		apple,always-on;
	};

	ps_nub_spmi_a0: power-controller@60 {
		compatible = "apple,t6050-pmgr-pwrstate", "apple,t8103-pmgr-pwrstate";
		reg = <0x60 4>;
		#power-domain-cells = <0>;
		#reset-cells = <0>;
		label = "nub_spmi_a0";
		apple,always-on;
	};

	ps_nub_spmi_a1: power-controller@68 {
		compatible = "apple,t6050-pmgr-pwrstate", "apple,t8103-pmgr-pwrstate";
		reg = <0x68 4>;
		#power-domain-cells = <0>;
		#reset-cells = <0>;
		label = "nub_spmi_a1";
		apple,always-on;
	};

	ps_nub_spmi_a2: power-controller@70 {
		compatible = "apple,t6050-pmgr-pwrstate", "apple,t8103-pmgr-pwrstate";
		reg = <0x70 4>;
		#power-domain-cells = <0>;
		#reset-cells = <0>;
		label = "nub_spmi_a2";
		apple,always-on;
	};

	ps_nub_aon: power-controller@78 {
		compatible = "apple,t6050-pmgr-pwrstate", "apple,t8103-pmgr-pwrstate";
		reg = <0x78 4>;
		#power-domain-cells = <0>;
		#reset-cells = <0>;
		label = "nub_aon";
		apple,always-on;
	};

	ps_nub_dock_channel: power-controller@80 {
		compatible = "apple,t6050-pmgr-pwrstate", "apple,t8103-pmgr-pwrstate";
		reg = <0x80 4>;
		#power-domain-cells = <0>;
		#reset-cells = <0>;
		label = "nub_dock_channel";
		apple,always-on;
		power-domains = <&ps_nub_aon>;
	};

	ps_nub_gpio: power-controller@88 {
		compatible = "apple,t6050-pmgr-pwrstate", "apple,t8103-pmgr-pwrstate";
		reg = <0x88 4>;
		#power-domain-cells = <0>;
		#reset-cells = <0>;
		label = "nub_gpio";
		apple,always-on;
	};

	ps_atc0_common_dp_0: power-controller@98 {
		compatible = "apple,t6050-pmgr-pwrstate", "apple,t8103-pmgr-pwrstate";
		reg = <0x98 4>;
		#power-domain-cells = <0>;
		#reset-cells = <0>;
		label = "atc0_common_dp_0";
	};

	ps_atc0_common_dp_1: power-controller@a0 {
		compatible = "apple,t6050-pmgr-pwrstate", "apple,t8103-pmgr-pwrstate";
		reg = <0xa0 4>;
		#power-domain-cells = <0>;
		#reset-cells = <0>;
		label = "atc0_common_dp_1";
	};

	ps_atc0_common_dp_2: power-controller@a8 {
		compatible = "apple,t6050-pmgr-pwrstate", "apple,t8103-pmgr-pwrstate";
		reg = <0xa8 4>;
		#power-domain-cells = <0>;
		#reset-cells = <0>;
		label = "atc0_common_dp_2";
	};

	ps_atc0_common_dp_3: power-controller@b0 {
		compatible = "apple,t6050-pmgr-pwrstate", "apple,t8103-pmgr-pwrstate";
		reg = <0xb0 4>;
		#power-domain-cells = <0>;
		#reset-cells = <0>;
		label = "atc0_common_dp_3";
	};

	ps_atc1_common_dp_0: power-controller@b8 {
		compatible = "apple,t6050-pmgr-pwrstate", "apple,t8103-pmgr-pwrstate";
		reg = <0xb8 4>;
		#power-domain-cells = <0>;
		#reset-cells = <0>;
		label = "atc1_common_dp_0";
	};

	ps_atc1_common_dp_1: power-controller@c0 {
		compatible = "apple,t6050-pmgr-pwrstate", "apple,t8103-pmgr-pwrstate";
		reg = <0xc0 4>;
		#power-domain-cells = <0>;
		#reset-cells = <0>;
		label = "atc1_common_dp_1";
	};

	ps_atc1_common_dp_2: power-controller@c8 {
		compatible = "apple,t6050-pmgr-pwrstate", "apple,t8103-pmgr-pwrstate";
		reg = <0xc8 4>;
		#power-domain-cells = <0>;
		#reset-cells = <0>;
		label = "atc1_common_dp_2";
	};

	ps_atc1_common_dp_3: power-controller@d0 {
		compatible = "apple,t6050-pmgr-pwrstate", "apple,t8103-pmgr-pwrstate";
		reg = <0xd0 4>;
		#power-domain-cells = <0>;
		#reset-cells = <0>;
		label = "atc1_common_dp_3";
	};

	ps_atc2_common_dp_0: power-controller@d8 {
		compatible = "apple,t6050-pmgr-pwrstate", "apple,t8103-pmgr-pwrstate";
		reg = <0xd8 4>;
		#power-domain-cells = <0>;
		#reset-cells = <0>;
		label = "atc2_common_dp_0";
	};

	ps_atc2_common_dp_1: power-controller@e0 {
		compatible = "apple,t6050-pmgr-pwrstate", "apple,t8103-pmgr-pwrstate";
		reg = <0xe0 4>;
		#power-domain-cells = <0>;
		#reset-cells = <0>;
		label = "atc2_common_dp_1";
	};

	ps_atc2_common_dp_2: power-controller@e8 {
		compatible = "apple,t6050-pmgr-pwrstate", "apple,t8103-pmgr-pwrstate";
		reg = <0xe8 4>;
		#power-domain-cells = <0>;
		#reset-cells = <0>;
		label = "atc2_common_dp_2";
	};

	ps_atc2_common_dp_3: power-controller@f0 {
		compatible = "apple,t6050-pmgr-pwrstate", "apple,t8103-pmgr-pwrstate";
		reg = <0xf0 4>;
		#power-domain-cells = <0>;
		#reset-cells = <0>;
		label = "atc2_common_dp_3";
	};

	ps_atc3_common_dp_0: power-controller@f8 {
		compatible = "apple,t6050-pmgr-pwrstate", "apple,t8103-pmgr-pwrstate";
		reg = <0xf8 4>;
		#power-domain-cells = <0>;
		#reset-cells = <0>;
		label = "atc3_common_dp_0";
	};

	ps_atc3_common_dp_1: power-controller@100 {
		compatible = "apple,t6050-pmgr-pwrstate", "apple,t8103-pmgr-pwrstate";
		reg = <0x100 4>;
		#power-domain-cells = <0>;
		#reset-cells = <0>;
		label = "atc3_common_dp_1";
	};

	ps_atc3_common_dp_2: power-controller@108 {
		compatible = "apple,t6050-pmgr-pwrstate", "apple,t8103-pmgr-pwrstate";
		reg = <0x108 4>;
		#power-domain-cells = <0>;
		#reset-cells = <0>;
		label = "atc3_common_dp_2";
	};

	ps_atc3_common_dp_3: power-controller@110 {
		compatible = "apple,t6050-pmgr-pwrstate", "apple,t8103-pmgr-pwrstate";
		reg = <0x110 4>;
		#power-domain-cells = <0>;
		#reset-cells = <0>;
		label = "atc3_common_dp_3";
	};

	ps_nub_spmi_ahb: power-controller@118 {
		compatible = "apple,t6050-pmgr-pwrstate", "apple,t8103-pmgr-pwrstate";
		reg = <0x118 4>;
		#power-domain-cells = <0>;
		#reset-cells = <0>;
		label = "nub_spmi_ahb";
		apple,always-on;
	};

	ps_nub_spmi0: power-controller@120 {
		compatible = "apple,t6050-pmgr-pwrstate", "apple,t8103-pmgr-pwrstate";
		reg = <0x120 4>;
		#power-domain-cells = <0>;
		#reset-cells = <0>;
		label = "nub_spmi0";
		apple,always-on;
		power-domains = <&ps_nub_spmi_ahb>;
	};

	ps_nub_spmi1: power-controller@128 {
		compatible = "apple,t6050-pmgr-pwrstate", "apple,t8103-pmgr-pwrstate";
		reg = <0x128 4>;
		#power-domain-cells = <0>;
		#reset-cells = <0>;
		label = "nub_spmi1";
		apple,always-on;
		power-domains = <&ps_nub_spmi_ahb>;
	};

	ps_nub_spmi2: power-controller@130 {
		compatible = "apple,t6050-pmgr-pwrstate", "apple,t8103-pmgr-pwrstate";
		reg = <0x130 4>;
		#power-domain-cells = <0>;
		#reset-cells = <0>;
		label = "nub_spmi2";
		apple,always-on;
		power-domains = <&ps_nub_spmi_ahb>;
	};

	ps_nub_spmi3: power-controller@138 {
		compatible = "apple,t6050-pmgr-pwrstate", "apple,t8103-pmgr-pwrstate";
		reg = <0x138 4>;
		#power-domain-cells = <0>;
		#reset-cells = <0>;
		label = "nub_spmi3";
		apple,always-on;
		power-domains = <&ps_nub_spmi_ahb>;
	};

	ps_nub_spmi4: power-controller@140 {
		compatible = "apple,t6050-pmgr-pwrstate", "apple,t8103-pmgr-pwrstate";
		reg = <0x140 4>;
		#power-domain-cells = <0>;
		#reset-cells = <0>;
		label = "nub_spmi4";
		apple,always-on;
		power-domains = <&ps_nub_spmi_ahb>;
	};

	ps_atc0_usb_aon: power-controller@148 {
		compatible = "apple,t6050-pmgr-pwrstate", "apple,t8103-pmgr-pwrstate";
		reg = <0x148 4>;
		#power-domain-cells = <0>;
		#reset-cells = <0>;
		label = "atc0_usb_aon";
	};

	ps_atc0_usb: power-controller@150 {
		compatible = "apple,t6050-pmgr-pwrstate", "apple,t8103-pmgr-pwrstate";
		reg = <0x150 4>;
		#power-domain-cells = <0>;
		#reset-cells = <0>;
		label = "atc0_usb";
		power-domains = <&ps_atc0_common>, <&ps_atc0_usb_aon>;
	};

	ps_atc0_phymxwrap: power-controller@158 {
		compatible = "apple,t6050-pmgr-pwrstate", "apple,t8103-pmgr-pwrstate";
		reg = <0x158 4>;
		#power-domain-cells = <0>;
		#reset-cells = <0>;
		label = "atc0_phymxwrap";
		power-domains = <&ps_atc0_common>, <&ps_atc0_usb_aon>;
	};

	ps_atc1_usb_aon: power-controller@160 {
		compatible = "apple,t6050-pmgr-pwrstate", "apple,t8103-pmgr-pwrstate";
		reg = <0x160 4>;
		#power-domain-cells = <0>;
		#reset-cells = <0>;
		label = "atc1_usb_aon";
	};

	ps_atc1_usb: power-controller@168 {
		compatible = "apple,t6050-pmgr-pwrstate", "apple,t8103-pmgr-pwrstate";
		reg = <0x168 4>;
		#power-domain-cells = <0>;
		#reset-cells = <0>;
		label = "atc1_usb";
		power-domains = <&ps_atc1_common>, <&ps_atc1_usb_aon>;
	};

	ps_atc1_phymxwrap: power-controller@170 {
		compatible = "apple,t6050-pmgr-pwrstate", "apple,t8103-pmgr-pwrstate";
		reg = <0x170 4>;
		#power-domain-cells = <0>;
		#reset-cells = <0>;
		label = "atc1_phymxwrap";
		power-domains = <&ps_atc1_common>, <&ps_atc1_usb_aon>;
	};

	ps_atc2_usb_aon: power-controller@178 {
		compatible = "apple,t6050-pmgr-pwrstate", "apple,t8103-pmgr-pwrstate";
		reg = <0x178 4>;
		#power-domain-cells = <0>;
		#reset-cells = <0>;
		label = "atc2_usb_aon";
	};

	ps_atc2_usb: power-controller@180 {
		compatible = "apple,t6050-pmgr-pwrstate", "apple,t8103-pmgr-pwrstate";
		reg = <0x180 4>;
		#power-domain-cells = <0>;
		#reset-cells = <0>;
		label = "atc2_usb";
		power-domains = <&ps_atc2_common>, <&ps_atc2_usb_aon>;
	};

	ps_atc2_phymxwrap: power-controller@188 {
		compatible = "apple,t6050-pmgr-pwrstate", "apple,t8103-pmgr-pwrstate";
		reg = <0x188 4>;
		#power-domain-cells = <0>;
		#reset-cells = <0>;
		label = "atc2_phymxwrap";
		power-domains = <&ps_atc2_common>, <&ps_atc2_usb_aon>;
	};

	ps_atc3_usb_aon: power-controller@190 {
		compatible = "apple,t6050-pmgr-pwrstate", "apple,t8103-pmgr-pwrstate";
		reg = <0x190 4>;
		#power-domain-cells = <0>;
		#reset-cells = <0>;
		label = "atc3_usb_aon";
	};

	ps_atc3_usb: power-controller@198 {
		compatible = "apple,t6050-pmgr-pwrstate", "apple,t8103-pmgr-pwrstate";
		reg = <0x198 4>;
		#power-domain-cells = <0>;
		#reset-cells = <0>;
		label = "atc3_usb";
		power-domains = <&ps_atc3_common>, <&ps_atc3_usb_aon>;
	};

	ps_atc3_phymxwrap: power-controller@1a0 {
		compatible = "apple,t6050-pmgr-pwrstate", "apple,t8103-pmgr-pwrstate";
		reg = <0x1a0 4>;
		#power-domain-cells = <0>;
		#reset-cells = <0>;
		label = "atc3_phymxwrap";
		power-domains = <&ps_atc3_common>, <&ps_atc3_usb_aon>;
	};

	ps_nub_fabric: power-controller@1a8 {
		compatible = "apple,t6050-pmgr-pwrstate", "apple,t8103-pmgr-pwrstate";
		reg = <0x1a8 4>;
		#power-domain-cells = <0>;
		#reset-cells = <0>;
		label = "nub_fabric";
		apple,always-on;
	};

	ps_nub_sram: power-controller@1b0 {
		compatible = "apple,t6050-pmgr-pwrstate", "apple,t8103-pmgr-pwrstate";
		reg = <0x1b0 4>;
		#power-domain-cells = <0>;
		#reset-cells = <0>;
		label = "nub_sram";
		apple,always-on;
		power-domains = <&ps_nub_fabric>;
	};

	ps_debug_switch: power-controller@1b8 {
		compatible = "apple,t6050-pmgr-pwrstate", "apple,t8103-pmgr-pwrstate";
		reg = <0x1b8 4>;
		#power-domain-cells = <0>;
		#reset-cells = <0>;
		label = "debug_switch";
		apple,always-on;
	};

	ps_smc_i2cm0: power-controller@8028 {
		compatible = "apple,t6050-pmgr-pwrstate", "apple,t8103-pmgr-pwrstate";
		reg = <0x8028 4>;
		#power-domain-cells = <0>;
		#reset-cells = <0>;
		label = "smc_i2cm0";
	};

	ps_smc_i2cm1: power-controller@8030 {
		compatible = "apple,t6050-pmgr-pwrstate", "apple,t8103-pmgr-pwrstate";
		reg = <0x8030 4>;
		#power-domain-cells = <0>;
		#reset-cells = <0>;
		label = "smc_i2cm1";
	};

	ps_smc_i2cm2: power-controller@8038 {
		compatible = "apple,t6050-pmgr-pwrstate", "apple,t8103-pmgr-pwrstate";
		reg = <0x8038 4>;
		#power-domain-cells = <0>;
		#reset-cells = <0>;
		label = "smc_i2cm2";
	};

	ps_smc_i2cm3: power-controller@8040 {
		compatible = "apple,t6050-pmgr-pwrstate", "apple,t8103-pmgr-pwrstate";
		reg = <0x8040 4>;
		#power-domain-cells = <0>;
		#reset-cells = <0>;
		label = "smc_i2cm3";
	};

	ps_smc_i2cm4: power-controller@8048 {
		compatible = "apple,t6050-pmgr-pwrstate", "apple,t8103-pmgr-pwrstate";
		reg = <0x8048 4>;
		#power-domain-cells = <0>;
		#reset-cells = <0>;
		label = "smc_i2cm4";
	};

	ps_smc_i2cm5: power-controller@8050 {
		compatible = "apple,t6050-pmgr-pwrstate", "apple,t8103-pmgr-pwrstate";
		reg = <0x8050 4>;
		#power-domain-cells = <0>;
		#reset-cells = <0>;
		label = "smc_i2cm5";
	};

	ps_smc_i2cm6: power-controller@8058 {
		compatible = "apple,t6050-pmgr-pwrstate", "apple,t8103-pmgr-pwrstate";
		reg = <0x8058 4>;
		#power-domain-cells = <0>;
		#reset-cells = <0>;
		label = "smc_i2cm6";
	};
};

&pmgr3 {

	ps_gpx: power-controller@0 {
		compatible = "apple,t6050-pmgr-pwrstate", "apple,t8103-pmgr-pwrstate";
		reg = <0x0 4>;
		#power-domain-cells = <0>;
		#reset-cells = <0>;
		label = "gpx";
		apple,always-on;
	};

	ps_afr: power-controller@100 {
		compatible = "apple,t6050-pmgr-pwrstate", "apple,t8103-pmgr-pwrstate";
		reg = <0x100 4>;
		#power-domain-cells = <0>;
		#reset-cells = <0>;
		label = "afr";
		apple,always-on;
	};

	ps_cs: power-controller@108 {
		compatible = "apple,t6050-pmgr-pwrstate", "apple,t8103-pmgr-pwrstate";
		reg = <0x108 4>;
		#power-domain-cells = <0>;
		#reset-cells = <0>;
		label = "cs";
		power-domains = <&ps_afr>;
	};

	ps_gfx: power-controller@110 {
		compatible = "apple,t6050-pmgr-pwrstate", "apple,t8103-pmgr-pwrstate";
		reg = <0x110 4>;
		#power-domain-cells = <0>;
		#reset-cells = <0>;
		label = "gfx";
		power-domains = <&ps_afr>, <&ps_gpx>;
	};
};

&pmgr4 {

	ps_pms_gfx: power-controller@100 {
		compatible = "apple,t6050-pmgr-pwrstate", "apple,t8103-pmgr-pwrstate";
		reg = <0x100 4>;
		#power-domain-cells = <0>;
		#reset-cells = <0>;
		label = "pms_gfx";
		apple,always-on;
	};

	ps_aic_gfx: power-controller@108 {
		compatible = "apple,t6050-pmgr-pwrstate", "apple,t8103-pmgr-pwrstate";
		reg = <0x108 4>;
		#power-domain-cells = <0>;
		#reset-cells = <0>;
		label = "aic_gfx";
		power-domains = <&ps_pms_gfx>;
	};

	ps_pms_gfx_c1ppt: power-controller@110 {
		compatible = "apple,t6050-pmgr-pwrstate", "apple,t8103-pmgr-pwrstate";
		reg = <0x110 4>;
		#power-domain-cells = <0>;
		#reset-cells = <0>;
		label = "pms_gfx_c1ppt";
		apple,always-on;
		power-domains = <&ps_pms_gfx>;
	};

	ps_soc_dpe_gfx: power-controller@118 {
		compatible = "apple,t6050-pmgr-pwrstate", "apple,t8103-pmgr-pwrstate";
		reg = <0x118 4>;
		#power-domain-cells = <0>;
		#reset-cells = <0>;
		label = "soc_dpe_gfx";
		apple,always-on;
		power-domains = <&ps_pms_gfx>;
	};

	ps_pmgr_soc_ocla_g: power-controller@120 {
		compatible = "apple,t6050-pmgr-pwrstate", "apple,t8103-pmgr-pwrstate";
		reg = <0x120 4>;
		#power-domain-cells = <0>;
		#reset-cells = <0>;
		label = "pmgr_soc_ocla_g";
	};

	ps_b2b_ctrl_gfx: power-controller@128 {
		compatible = "apple,t6050-pmgr-pwrstate", "apple,t8103-pmgr-pwrstate";
		reg = <0x128 4>;
		#power-domain-cells = <0>;
		#reset-cells = <0>;
		label = "b2b_ctrl_gfx";
	};

	ps_b2bg_afc_0: power-controller@130 {
		compatible = "apple,t6050-pmgr-pwrstate", "apple,t8103-pmgr-pwrstate";
		reg = <0x130 4>;
		#power-domain-cells = <0>;
		#reset-cells = <0>;
		label = "b2bg_afc_0";
		apple,always-on;
	};

	ps_b2bg_afc_0_dfx: power-controller@138 {
		compatible = "apple,t6050-pmgr-pwrstate", "apple,t8103-pmgr-pwrstate";
		reg = <0x138 4>;
		#power-domain-cells = <0>;
		#reset-cells = <0>;
		label = "b2bg_afc_0_dfx";
		apple,always-on;
		power-domains = <&ps_b2bg_afc_0>;
	};

	ps_b2bg_afc_1: power-controller@140 {
		compatible = "apple,t6050-pmgr-pwrstate", "apple,t8103-pmgr-pwrstate";
		reg = <0x140 4>;
		#power-domain-cells = <0>;
		#reset-cells = <0>;
		label = "b2bg_afc_1";
		apple,always-on;
	};

	ps_b2bg_afc_1_dfx: power-controller@148 {
		compatible = "apple,t6050-pmgr-pwrstate", "apple,t8103-pmgr-pwrstate";
		reg = <0x148 4>;
		#power-domain-cells = <0>;
		#reset-cells = <0>;
		label = "b2bg_afc_1_dfx";
		apple,always-on;
		power-domains = <&ps_b2bg_afc_1>;
	};

	ps_fab1_afi_0: power-controller@150 {
		compatible = "apple,t6050-pmgr-pwrstate", "apple,t8103-pmgr-pwrstate";
		reg = <0x150 4>;
		#power-domain-cells = <0>;
		#reset-cells = <0>;
		label = "fab1_afi_0";
		apple,always-on;
	};

	ps_fab1_afi_1: power-controller@158 {
		compatible = "apple,t6050-pmgr-pwrstate", "apple,t8103-pmgr-pwrstate";
		reg = <0x158 4>;
		#power-domain-cells = <0>;
		#reset-cells = <0>;
		label = "fab1_afi_1";
		apple,always-on;
	};

	ps_fab_b2bg_afi_0: power-controller@160 {
		compatible = "apple,t6050-pmgr-pwrstate", "apple,t8103-pmgr-pwrstate";
		reg = <0x160 4>;
		#power-domain-cells = <0>;
		#reset-cells = <0>;
		label = "fab_b2bg_afi_0";
		apple,always-on;
	};

	ps_fab_b2bg_afi_1: power-controller@168 {
		compatible = "apple,t6050-pmgr-pwrstate", "apple,t8103-pmgr-pwrstate";
		reg = <0x168 4>;
		#power-domain-cells = <0>;
		#reset-cells = <0>;
		label = "fab_b2bg_afi_1";
		apple,always-on;
	};

	ps_b2bg_afi_0: power-controller@170 {
		compatible = "apple,t6050-pmgr-pwrstate", "apple,t8103-pmgr-pwrstate";
		reg = <0x170 4>;
		#power-domain-cells = <0>;
		#reset-cells = <0>;
		label = "b2bg_afi_0";
		apple,always-on;
	};

	ps_b2bg_afi_0_dfx: power-controller@178 {
		compatible = "apple,t6050-pmgr-pwrstate", "apple,t8103-pmgr-pwrstate";
		reg = <0x178 4>;
		#power-domain-cells = <0>;
		#reset-cells = <0>;
		label = "b2bg_afi_0_dfx";
		apple,always-on;
		power-domains = <&ps_b2bg_afi_0>;
	};

	ps_b2bg_afi_1: power-controller@180 {
		compatible = "apple,t6050-pmgr-pwrstate", "apple,t8103-pmgr-pwrstate";
		reg = <0x180 4>;
		#power-domain-cells = <0>;
		#reset-cells = <0>;
		label = "b2bg_afi_1";
		apple,always-on;
	};

	ps_b2bg_afi_1_dfx: power-controller@188 {
		compatible = "apple,t6050-pmgr-pwrstate", "apple,t8103-pmgr-pwrstate";
		reg = <0x188 4>;
		#power-domain-cells = <0>;
		#reset-cells = <0>;
		label = "b2bg_afi_1_dfx";
		apple,always-on;
		power-domains = <&ps_b2bg_afi_1>;
	};

	ps_fab1_afigw: power-controller@190 {
		compatible = "apple,t6050-pmgr-pwrstate", "apple,t8103-pmgr-pwrstate";
		reg = <0x190 4>;
		#power-domain-cells = <0>;
		#reset-cells = <0>;
		label = "fab1_afigw";
		apple,always-on;
	};

	ps_fppt_gfx: power-controller@198 {
		compatible = "apple,t6050-pmgr-pwrstate", "apple,t8103-pmgr-pwrstate";
		reg = <0x198 4>;
		#power-domain-cells = <0>;
		#reset-cells = <0>;
		label = "fppt_gfx";
		power-domains = <&ps_fab1_afigw>;
	};

	ps_fab1_piogw: power-controller@1a0 {
		compatible = "apple,t6050-pmgr-pwrstate", "apple,t8103-pmgr-pwrstate";
		reg = <0x1a0 4>;
		#power-domain-cells = <0>;
		#reset-cells = <0>;
		label = "fab1_piogw";
		apple,always-on;
	};

	ps_fab0_soc: power-controller@1a8 {
		compatible = "apple,t6050-pmgr-pwrstate", "apple,t8103-pmgr-pwrstate";
		reg = <0x1a8 4>;
		#power-domain-cells = <0>;
		#reset-cells = <0>;
		label = "fab0_soc";
		apple,always-on;
		power-domains = <&ps_fab1_piogw>;
	};

	ps_fab1_soc: power-controller@1b0 {
		compatible = "apple,t6050-pmgr-pwrstate", "apple,t8103-pmgr-pwrstate";
		reg = <0x1b0 4>;
		#power-domain-cells = <0>;
		#reset-cells = <0>;
		label = "fab1_soc";
		apple,always-on;
		power-domains = <&ps_fab1_piogw>;
	};

	ps_fab2_soc: power-controller@1b8 {
		compatible = "apple,t6050-pmgr-pwrstate", "apple,t8103-pmgr-pwrstate";
		reg = <0x1b8 4>;
		#power-domain-cells = <0>;
		#reset-cells = <0>;
		label = "fab2_soc";
		apple,always-on;
		power-domains = <&ps_fab1_piogw>;
	};

	ps_venc0_sys: power-controller@1c0 {
		compatible = "apple,t6050-pmgr-pwrstate", "apple,t8103-pmgr-pwrstate";
		reg = <0x1c0 4>;
		#power-domain-cells = <0>;
		#reset-cells = <0>;
		label = "venc0_sys";
		power-domains = <&ps_fab0_soc>;
	};

	ps_msr0: power-controller@1c8 {
		compatible = "apple,t6050-pmgr-pwrstate", "apple,t8103-pmgr-pwrstate";
		reg = <0x1c8 4>;
		#power-domain-cells = <0>;
		#reset-cells = <0>;
		label = "msr0";
		power-domains = <&ps_fab0_soc>;
	};

	ps_jpg: power-controller@1d0 {
		compatible = "apple,t6050-pmgr-pwrstate", "apple,t8103-pmgr-pwrstate";
		reg = <0x1d0 4>;
		#power-domain-cells = <0>;
		#reset-cells = <0>;
		label = "jpg";
		power-domains = <&ps_fab0_soc>;
	};

	ps_avd_sys: power-controller@1d8 {
		compatible = "apple,t6050-pmgr-pwrstate", "apple,t8103-pmgr-pwrstate";
		reg = <0x1d8 4>;
		#power-domain-cells = <0>;
		#reset-cells = <0>;
		label = "avd_sys";
		power-domains = <&ps_fab1_soc>;
	};

	ps_prores: power-controller@1e0 {
		compatible = "apple,t6050-pmgr-pwrstate", "apple,t8103-pmgr-pwrstate";
		reg = <0x1e0 4>;
		#power-domain-cells = <0>;
		#reset-cells = <0>;
		label = "prores";
		power-domains = <&ps_fab1_soc>;
	};

	ps_sbr_gfx: power-controller@1e8 {
		compatible = "apple,t6050-pmgr-pwrstate", "apple,t8103-pmgr-pwrstate";
		reg = <0x1e8 4>;
		#power-domain-cells = <0>;
		#reset-cells = <0>;
		label = "sbr_gfx";
		apple,always-on;
		power-domains = <&ps_fab2_soc>;
	};

	ps_venc1_sys: power-controller@1f0 {
		compatible = "apple,t6050-pmgr-pwrstate", "apple,t8103-pmgr-pwrstate";
		reg = <0x1f0 4>;
		#power-domain-cells = <0>;
		#reset-cells = <0>;
		label = "venc1_sys";
		power-domains = <&ps_fab2_soc>;
	};

	ps_msr1: power-controller@1f8 {
		compatible = "apple,t6050-pmgr-pwrstate", "apple,t8103-pmgr-pwrstate";
		reg = <0x1f8 4>;
		#power-domain-cells = <0>;
		#reset-cells = <0>;
		label = "msr1";
		power-domains = <&ps_fab2_soc>;
	};

	ps_msr0_ase_core: power-controller@200 {
		compatible = "apple,t6050-pmgr-pwrstate", "apple,t8103-pmgr-pwrstate";
		reg = <0x200 4>;
		#power-domain-cells = <0>;
		#reset-cells = <0>;
		label = "msr0_ase_core";
		power-domains = <&ps_msr0>;
	};

	ps_msr1_ase_core: power-controller@208 {
		compatible = "apple,t6050-pmgr-pwrstate", "apple,t8103-pmgr-pwrstate";
		reg = <0x208 4>;
		#power-domain-cells = <0>;
		#reset-cells = <0>;
		label = "msr1_ase_core";
		power-domains = <&ps_msr1>;
	};

	ps_fab_afi_amcc_0: power-controller@210 {
		compatible = "apple,t6050-pmgr-pwrstate", "apple,t8103-pmgr-pwrstate";
		reg = <0x210 4>;
		#power-domain-cells = <0>;
		#reset-cells = <0>;
		label = "fab_afi_amcc_0";
		apple,always-on;
	};

	ps_amcc0: power-controller@218 {
		compatible = "apple,t6050-pmgr-pwrstate", "apple,t8103-pmgr-pwrstate";
		reg = <0x218 4>;
		#power-domain-cells = <0>;
		#reset-cells = <0>;
		label = "amcc0";
		apple,always-on;
		power-domains = <&ps_fab_afi_amcc_0>;
	};

	ps_amcc1: power-controller@220 {
		compatible = "apple,t6050-pmgr-pwrstate", "apple,t8103-pmgr-pwrstate";
		reg = <0x220 4>;
		#power-domain-cells = <0>;
		#reset-cells = <0>;
		label = "amcc1";
		apple,always-on;
		power-domains = <&ps_fab_afi_amcc_0>;
	};

	ps_amcc2: power-controller@228 {
		compatible = "apple,t6050-pmgr-pwrstate", "apple,t8103-pmgr-pwrstate";
		reg = <0x228 4>;
		#power-domain-cells = <0>;
		#reset-cells = <0>;
		label = "amcc2";
		apple,always-on;
		power-domains = <&ps_fab_afi_amcc_0>;
	};

	ps_amcc3: power-controller@230 {
		compatible = "apple,t6050-pmgr-pwrstate", "apple,t8103-pmgr-pwrstate";
		reg = <0x230 4>;
		#power-domain-cells = <0>;
		#reset-cells = <0>;
		label = "amcc3";
		apple,always-on;
		power-domains = <&ps_fab_afi_amcc_0>;
	};

	ps_fab_afr_amcc_0: power-controller@238 {
		compatible = "apple,t6050-pmgr-pwrstate", "apple,t8103-pmgr-pwrstate";
		reg = <0x238 4>;
		#power-domain-cells = <0>;
		#reset-cells = <0>;
		label = "fab_afr_amcc_0";
		apple,always-on;
		power-domains = <&ps_fab_afi_amcc_0>;
	};

	ps_fab_afr_amcc_1: power-controller@240 {
		compatible = "apple,t6050-pmgr-pwrstate", "apple,t8103-pmgr-pwrstate";
		reg = <0x240 4>;
		#power-domain-cells = <0>;
		#reset-cells = <0>;
		label = "fab_afr_amcc_1";
		apple,always-on;
		power-domains = <&ps_fab_afi_amcc_0>;
	};

	ps_dcs_00: power-controller@248 {
		compatible = "apple,t6050-pmgr-pwrstate", "apple,t8103-pmgr-pwrstate";
		reg = <0x248 4>;
		#power-domain-cells = <0>;
		#reset-cells = <0>;
		label = "dcs_00";
		apple,always-on;
		power-domains = <&ps_amcc0>;
	};

	ps_dcs_01: power-controller@258 {
		compatible = "apple,t6050-pmgr-pwrstate", "apple,t8103-pmgr-pwrstate";
		reg = <0x258 4>;
		#power-domain-cells = <0>;
		#reset-cells = <0>;
		label = "dcs_01";
		apple,always-on;
		power-domains = <&ps_amcc1>;
	};

	ps_dcs_02: power-controller@268 {
		compatible = "apple,t6050-pmgr-pwrstate", "apple,t8103-pmgr-pwrstate";
		reg = <0x268 4>;
		#power-domain-cells = <0>;
		#reset-cells = <0>;
		label = "dcs_02";
		apple,always-on;
		power-domains = <&ps_amcc2>;
	};

	ps_dcs_03: power-controller@278 {
		compatible = "apple,t6050-pmgr-pwrstate", "apple,t8103-pmgr-pwrstate";
		reg = <0x278 4>;
		#power-domain-cells = <0>;
		#reset-cells = <0>;
		label = "dcs_03";
		apple,always-on;
		power-domains = <&ps_amcc3>;
	};

	ps_fab_afc_amcc_0: power-controller@288 {
		compatible = "apple,t6050-pmgr-pwrstate", "apple,t8103-pmgr-pwrstate";
		reg = <0x288 4>;
		#power-domain-cells = <0>;
		#reset-cells = <0>;
		label = "fab_afc_amcc_0";
		apple,always-on;
	};

	ps_fab_afi_amcc_1: power-controller@290 {
		compatible = "apple,t6050-pmgr-pwrstate", "apple,t8103-pmgr-pwrstate";
		reg = <0x290 4>;
		#power-domain-cells = <0>;
		#reset-cells = <0>;
		label = "fab_afi_amcc_1";
		apple,always-on;
	};

	ps_amcc4: power-controller@298 {
		compatible = "apple,t6050-pmgr-pwrstate", "apple,t8103-pmgr-pwrstate";
		reg = <0x298 4>;
		#power-domain-cells = <0>;
		#reset-cells = <0>;
		label = "amcc4";
		apple,always-on;
		power-domains = <&ps_fab_afi_amcc_1>;
	};

	ps_amcc5: power-controller@2a0 {
		compatible = "apple,t6050-pmgr-pwrstate", "apple,t8103-pmgr-pwrstate";
		reg = <0x2a0 4>;
		#power-domain-cells = <0>;
		#reset-cells = <0>;
		label = "amcc5";
		apple,always-on;
		power-domains = <&ps_fab_afi_amcc_1>;
	};

	ps_amcc6: power-controller@2a8 {
		compatible = "apple,t6050-pmgr-pwrstate", "apple,t8103-pmgr-pwrstate";
		reg = <0x2a8 4>;
		#power-domain-cells = <0>;
		#reset-cells = <0>;
		label = "amcc6";
		apple,always-on;
		power-domains = <&ps_fab_afi_amcc_1>;
	};

	ps_amcc7: power-controller@2b0 {
		compatible = "apple,t6050-pmgr-pwrstate", "apple,t8103-pmgr-pwrstate";
		reg = <0x2b0 4>;
		#power-domain-cells = <0>;
		#reset-cells = <0>;
		label = "amcc7";
		apple,always-on;
		power-domains = <&ps_fab_afi_amcc_1>;
	};

	ps_fab_afr_amcc_2: power-controller@2b8 {
		compatible = "apple,t6050-pmgr-pwrstate", "apple,t8103-pmgr-pwrstate";
		reg = <0x2b8 4>;
		#power-domain-cells = <0>;
		#reset-cells = <0>;
		label = "fab_afr_amcc_2";
		apple,always-on;
		power-domains = <&ps_fab_afi_amcc_1>;
	};

	ps_fab_afr_amcc_3: power-controller@2c0 {
		compatible = "apple,t6050-pmgr-pwrstate", "apple,t8103-pmgr-pwrstate";
		reg = <0x2c0 4>;
		#power-domain-cells = <0>;
		#reset-cells = <0>;
		label = "fab_afr_amcc_3";
		apple,always-on;
		power-domains = <&ps_fab_afi_amcc_1>;
	};

	ps_dcs_04: power-controller@2c8 {
		compatible = "apple,t6050-pmgr-pwrstate", "apple,t8103-pmgr-pwrstate";
		reg = <0x2c8 4>;
		#power-domain-cells = <0>;
		#reset-cells = <0>;
		label = "dcs_04";
		apple,always-on;
		power-domains = <&ps_amcc4>;
	};

	ps_dcs_05: power-controller@2d8 {
		compatible = "apple,t6050-pmgr-pwrstate", "apple,t8103-pmgr-pwrstate";
		reg = <0x2d8 4>;
		#power-domain-cells = <0>;
		#reset-cells = <0>;
		label = "dcs_05";
		apple,always-on;
		power-domains = <&ps_amcc5>;
	};

	ps_dcs_06: power-controller@2e8 {
		compatible = "apple,t6050-pmgr-pwrstate", "apple,t8103-pmgr-pwrstate";
		reg = <0x2e8 4>;
		#power-domain-cells = <0>;
		#reset-cells = <0>;
		label = "dcs_06";
		apple,always-on;
		power-domains = <&ps_amcc6>;
	};

	ps_dcs_07: power-controller@2f8 {
		compatible = "apple,t6050-pmgr-pwrstate", "apple,t8103-pmgr-pwrstate";
		reg = <0x2f8 4>;
		#power-domain-cells = <0>;
		#reset-cells = <0>;
		label = "dcs_07";
		apple,always-on;
		power-domains = <&ps_amcc7>;
	};

	ps_fab_afc_amcc_1: power-controller@308 {
		compatible = "apple,t6050-pmgr-pwrstate", "apple,t8103-pmgr-pwrstate";
		reg = <0x308 4>;
		#power-domain-cells = <0>;
		#reset-cells = <0>;
		label = "fab_afc_amcc_1";
		apple,always-on;
	};

	ps_fab_afi_amcc_2: power-controller@310 {
		compatible = "apple,t6050-pmgr-pwrstate", "apple,t8103-pmgr-pwrstate";
		reg = <0x310 4>;
		#power-domain-cells = <0>;
		#reset-cells = <0>;
		label = "fab_afi_amcc_2";
		apple,always-on;
	};

	ps_amcc8: power-controller@318 {
		compatible = "apple,t6050-pmgr-pwrstate", "apple,t8103-pmgr-pwrstate";
		reg = <0x318 4>;
		#power-domain-cells = <0>;
		#reset-cells = <0>;
		label = "amcc8";
		apple,always-on;
		power-domains = <&ps_fab_afi_amcc_2>;
	};

	ps_amcc9: power-controller@320 {
		compatible = "apple,t6050-pmgr-pwrstate", "apple,t8103-pmgr-pwrstate";
		reg = <0x320 4>;
		#power-domain-cells = <0>;
		#reset-cells = <0>;
		label = "amcc9";
		apple,always-on;
		power-domains = <&ps_fab_afi_amcc_2>;
	};

	ps_amcc10: power-controller@328 {
		compatible = "apple,t6050-pmgr-pwrstate", "apple,t8103-pmgr-pwrstate";
		reg = <0x328 4>;
		#power-domain-cells = <0>;
		#reset-cells = <0>;
		label = "amcc10";
		apple,always-on;
		power-domains = <&ps_fab_afi_amcc_2>;
	};

	ps_amcc11: power-controller@330 {
		compatible = "apple,t6050-pmgr-pwrstate", "apple,t8103-pmgr-pwrstate";
		reg = <0x330 4>;
		#power-domain-cells = <0>;
		#reset-cells = <0>;
		label = "amcc11";
		apple,always-on;
		power-domains = <&ps_fab_afi_amcc_2>;
	};

	ps_fab_afr_amcc_4: power-controller@338 {
		compatible = "apple,t6050-pmgr-pwrstate", "apple,t8103-pmgr-pwrstate";
		reg = <0x338 4>;
		#power-domain-cells = <0>;
		#reset-cells = <0>;
		label = "fab_afr_amcc_4";
		apple,always-on;
		power-domains = <&ps_fab_afi_amcc_2>;
	};

	ps_fab_afr_amcc_5: power-controller@340 {
		compatible = "apple,t6050-pmgr-pwrstate", "apple,t8103-pmgr-pwrstate";
		reg = <0x340 4>;
		#power-domain-cells = <0>;
		#reset-cells = <0>;
		label = "fab_afr_amcc_5";
		apple,always-on;
		power-domains = <&ps_fab_afi_amcc_2>;
	};

	ps_dcs_08: power-controller@348 {
		compatible = "apple,t6050-pmgr-pwrstate", "apple,t8103-pmgr-pwrstate";
		reg = <0x348 4>;
		#power-domain-cells = <0>;
		#reset-cells = <0>;
		label = "dcs_08";
		apple,always-on;
		power-domains = <&ps_amcc8>;
	};

	ps_dcs_09: power-controller@358 {
		compatible = "apple,t6050-pmgr-pwrstate", "apple,t8103-pmgr-pwrstate";
		reg = <0x358 4>;
		#power-domain-cells = <0>;
		#reset-cells = <0>;
		label = "dcs_09";
		apple,always-on;
		power-domains = <&ps_amcc9>;
	};

	ps_dcs_10: power-controller@368 {
		compatible = "apple,t6050-pmgr-pwrstate", "apple,t8103-pmgr-pwrstate";
		reg = <0x368 4>;
		#power-domain-cells = <0>;
		#reset-cells = <0>;
		label = "dcs_10";
		apple,always-on;
		power-domains = <&ps_amcc10>;
	};

	ps_dcs_11: power-controller@378 {
		compatible = "apple,t6050-pmgr-pwrstate", "apple,t8103-pmgr-pwrstate";
		reg = <0x378 4>;
		#power-domain-cells = <0>;
		#reset-cells = <0>;
		label = "dcs_11";
		apple,always-on;
		power-domains = <&ps_amcc11>;
	};

	ps_fab_afc_amcc_2: power-controller@388 {
		compatible = "apple,t6050-pmgr-pwrstate", "apple,t8103-pmgr-pwrstate";
		reg = <0x388 4>;
		#power-domain-cells = <0>;
		#reset-cells = <0>;
		label = "fab_afc_amcc_2";
		apple,always-on;
	};

	ps_fab_afi_amcc_3: power-controller@390 {
		compatible = "apple,t6050-pmgr-pwrstate", "apple,t8103-pmgr-pwrstate";
		reg = <0x390 4>;
		#power-domain-cells = <0>;
		#reset-cells = <0>;
		label = "fab_afi_amcc_3";
		apple,always-on;
	};

	ps_amcc12: power-controller@398 {
		compatible = "apple,t6050-pmgr-pwrstate", "apple,t8103-pmgr-pwrstate";
		reg = <0x398 4>;
		#power-domain-cells = <0>;
		#reset-cells = <0>;
		label = "amcc12";
		apple,always-on;
		power-domains = <&ps_fab_afi_amcc_3>;
	};

	ps_amcc13: power-controller@3a0 {
		compatible = "apple,t6050-pmgr-pwrstate", "apple,t8103-pmgr-pwrstate";
		reg = <0x3a0 4>;
		#power-domain-cells = <0>;
		#reset-cells = <0>;
		label = "amcc13";
		apple,always-on;
		power-domains = <&ps_fab_afi_amcc_3>;
	};

	ps_amcc14: power-controller@3a8 {
		compatible = "apple,t6050-pmgr-pwrstate", "apple,t8103-pmgr-pwrstate";
		reg = <0x3a8 4>;
		#power-domain-cells = <0>;
		#reset-cells = <0>;
		label = "amcc14";
		apple,always-on;
		power-domains = <&ps_fab_afi_amcc_3>;
	};

	ps_amcc15: power-controller@3b0 {
		compatible = "apple,t6050-pmgr-pwrstate", "apple,t8103-pmgr-pwrstate";
		reg = <0x3b0 4>;
		#power-domain-cells = <0>;
		#reset-cells = <0>;
		label = "amcc15";
		apple,always-on;
		power-domains = <&ps_fab_afi_amcc_3>;
	};

	ps_fab_afr_amcc_6: power-controller@3b8 {
		compatible = "apple,t6050-pmgr-pwrstate", "apple,t8103-pmgr-pwrstate";
		reg = <0x3b8 4>;
		#power-domain-cells = <0>;
		#reset-cells = <0>;
		label = "fab_afr_amcc_6";
		apple,always-on;
		power-domains = <&ps_fab_afi_amcc_3>;
	};

	ps_fab_afr_amcc_7: power-controller@3c0 {
		compatible = "apple,t6050-pmgr-pwrstate", "apple,t8103-pmgr-pwrstate";
		reg = <0x3c0 4>;
		#power-domain-cells = <0>;
		#reset-cells = <0>;
		label = "fab_afr_amcc_7";
		apple,always-on;
		power-domains = <&ps_fab_afi_amcc_3>;
	};

	ps_dcs_12: power-controller@3c8 {
		compatible = "apple,t6050-pmgr-pwrstate", "apple,t8103-pmgr-pwrstate";
		reg = <0x3c8 4>;
		#power-domain-cells = <0>;
		#reset-cells = <0>;
		label = "dcs_12";
		apple,always-on;
		power-domains = <&ps_amcc12>;
	};

	ps_dcs_13: power-controller@3d8 {
		compatible = "apple,t6050-pmgr-pwrstate", "apple,t8103-pmgr-pwrstate";
		reg = <0x3d8 4>;
		#power-domain-cells = <0>;
		#reset-cells = <0>;
		label = "dcs_13";
		apple,always-on;
		power-domains = <&ps_amcc13>;
	};

	ps_dcs_14: power-controller@3e8 {
		compatible = "apple,t6050-pmgr-pwrstate", "apple,t8103-pmgr-pwrstate";
		reg = <0x3e8 4>;
		#power-domain-cells = <0>;
		#reset-cells = <0>;
		label = "dcs_14";
		apple,always-on;
		power-domains = <&ps_amcc14>;
	};

	ps_dcs_15: power-controller@3f8 {
		compatible = "apple,t6050-pmgr-pwrstate", "apple,t8103-pmgr-pwrstate";
		reg = <0x3f8 4>;
		#power-domain-cells = <0>;
		#reset-cells = <0>;
		label = "dcs_15";
		apple,always-on;
		power-domains = <&ps_amcc15>;
	};

	ps_fab_afc_amcc_3: power-controller@408 {
		compatible = "apple,t6050-pmgr-pwrstate", "apple,t8103-pmgr-pwrstate";
		reg = <0x408 4>;
		#power-domain-cells = <0>;
		#reset-cells = <0>;
		label = "fab_afc_amcc_3";
		apple,always-on;
	};

	ps_fab_afi_amcc_4: power-controller@410 {
		compatible = "apple,t6050-pmgr-pwrstate", "apple,t8103-pmgr-pwrstate";
		reg = <0x410 4>;
		#power-domain-cells = <0>;
		#reset-cells = <0>;
		label = "fab_afi_amcc_4";
		apple,always-on;
	};

	ps_amcc16: power-controller@418 {
		compatible = "apple,t6050-pmgr-pwrstate", "apple,t8103-pmgr-pwrstate";
		reg = <0x418 4>;
		#power-domain-cells = <0>;
		#reset-cells = <0>;
		label = "amcc16";
		apple,always-on;
		power-domains = <&ps_fab_afi_amcc_4>;
	};

	ps_amcc17: power-controller@420 {
		compatible = "apple,t6050-pmgr-pwrstate", "apple,t8103-pmgr-pwrstate";
		reg = <0x420 4>;
		#power-domain-cells = <0>;
		#reset-cells = <0>;
		label = "amcc17";
		apple,always-on;
		power-domains = <&ps_fab_afi_amcc_4>;
	};

	ps_amcc18: power-controller@428 {
		compatible = "apple,t6050-pmgr-pwrstate", "apple,t8103-pmgr-pwrstate";
		reg = <0x428 4>;
		#power-domain-cells = <0>;
		#reset-cells = <0>;
		label = "amcc18";
		apple,always-on;
		power-domains = <&ps_fab_afi_amcc_4>;
	};

	ps_amcc19: power-controller@430 {
		compatible = "apple,t6050-pmgr-pwrstate", "apple,t8103-pmgr-pwrstate";
		reg = <0x430 4>;
		#power-domain-cells = <0>;
		#reset-cells = <0>;
		label = "amcc19";
		apple,always-on;
		power-domains = <&ps_fab_afi_amcc_4>;
	};

	ps_fab_afr_amcc_8: power-controller@438 {
		compatible = "apple,t6050-pmgr-pwrstate", "apple,t8103-pmgr-pwrstate";
		reg = <0x438 4>;
		#power-domain-cells = <0>;
		#reset-cells = <0>;
		label = "fab_afr_amcc_8";
		apple,always-on;
		power-domains = <&ps_fab_afi_amcc_4>;
	};

	ps_fab_afr_amcc_9: power-controller@440 {
		compatible = "apple,t6050-pmgr-pwrstate", "apple,t8103-pmgr-pwrstate";
		reg = <0x440 4>;
		#power-domain-cells = <0>;
		#reset-cells = <0>;
		label = "fab_afr_amcc_9";
		apple,always-on;
		power-domains = <&ps_fab_afi_amcc_4>;
	};

	ps_dcs_16: power-controller@448 {
		compatible = "apple,t6050-pmgr-pwrstate", "apple,t8103-pmgr-pwrstate";
		reg = <0x448 4>;
		#power-domain-cells = <0>;
		#reset-cells = <0>;
		label = "dcs_16";
		apple,always-on;
		power-domains = <&ps_amcc16>;
	};

	ps_dcs_17: power-controller@458 {
		compatible = "apple,t6050-pmgr-pwrstate", "apple,t8103-pmgr-pwrstate";
		reg = <0x458 4>;
		#power-domain-cells = <0>;
		#reset-cells = <0>;
		label = "dcs_17";
		apple,always-on;
		power-domains = <&ps_amcc17>;
	};

	ps_dcs_18: power-controller@468 {
		compatible = "apple,t6050-pmgr-pwrstate", "apple,t8103-pmgr-pwrstate";
		reg = <0x468 4>;
		#power-domain-cells = <0>;
		#reset-cells = <0>;
		label = "dcs_18";
		apple,always-on;
		power-domains = <&ps_amcc18>;
	};

	ps_dcs_19: power-controller@478 {
		compatible = "apple,t6050-pmgr-pwrstate", "apple,t8103-pmgr-pwrstate";
		reg = <0x478 4>;
		#power-domain-cells = <0>;
		#reset-cells = <0>;
		label = "dcs_19";
		apple,always-on;
		power-domains = <&ps_amcc19>;
	};

	ps_fab_afc_amcc_4: power-controller@488 {
		compatible = "apple,t6050-pmgr-pwrstate", "apple,t8103-pmgr-pwrstate";
		reg = <0x488 4>;
		#power-domain-cells = <0>;
		#reset-cells = <0>;
		label = "fab_afc_amcc_4";
		apple,always-on;
	};

	ps_fab_afi_amcc_5: power-controller@490 {
		compatible = "apple,t6050-pmgr-pwrstate", "apple,t8103-pmgr-pwrstate";
		reg = <0x490 4>;
		#power-domain-cells = <0>;
		#reset-cells = <0>;
		label = "fab_afi_amcc_5";
		apple,always-on;
	};

	ps_amcc20: power-controller@498 {
		compatible = "apple,t6050-pmgr-pwrstate", "apple,t8103-pmgr-pwrstate";
		reg = <0x498 4>;
		#power-domain-cells = <0>;
		#reset-cells = <0>;
		label = "amcc20";
		apple,always-on;
		power-domains = <&ps_fab_afi_amcc_5>;
	};

	ps_amcc21: power-controller@4a0 {
		compatible = "apple,t6050-pmgr-pwrstate", "apple,t8103-pmgr-pwrstate";
		reg = <0x4a0 4>;
		#power-domain-cells = <0>;
		#reset-cells = <0>;
		label = "amcc21";
		apple,always-on;
		power-domains = <&ps_fab_afi_amcc_5>;
	};

	ps_amcc22: power-controller@4a8 {
		compatible = "apple,t6050-pmgr-pwrstate", "apple,t8103-pmgr-pwrstate";
		reg = <0x4a8 4>;
		#power-domain-cells = <0>;
		#reset-cells = <0>;
		label = "amcc22";
		apple,always-on;
		power-domains = <&ps_fab_afi_amcc_5>;
	};

	ps_amcc23: power-controller@4b0 {
		compatible = "apple,t6050-pmgr-pwrstate", "apple,t8103-pmgr-pwrstate";
		reg = <0x4b0 4>;
		#power-domain-cells = <0>;
		#reset-cells = <0>;
		label = "amcc23";
		apple,always-on;
		power-domains = <&ps_fab_afi_amcc_5>;
	};

	ps_fab_afr_amcc_10: power-controller@4b8 {
		compatible = "apple,t6050-pmgr-pwrstate", "apple,t8103-pmgr-pwrstate";
		reg = <0x4b8 4>;
		#power-domain-cells = <0>;
		#reset-cells = <0>;
		label = "fab_afr_amcc_10";
		apple,always-on;
		power-domains = <&ps_fab_afi_amcc_5>;
	};

	ps_fab_afr_amcc_11: power-controller@4c0 {
		compatible = "apple,t6050-pmgr-pwrstate", "apple,t8103-pmgr-pwrstate";
		reg = <0x4c0 4>;
		#power-domain-cells = <0>;
		#reset-cells = <0>;
		label = "fab_afr_amcc_11";
		apple,always-on;
		power-domains = <&ps_fab_afi_amcc_5>;
	};

	ps_dcs_20: power-controller@4c8 {
		compatible = "apple,t6050-pmgr-pwrstate", "apple,t8103-pmgr-pwrstate";
		reg = <0x4c8 4>;
		#power-domain-cells = <0>;
		#reset-cells = <0>;
		label = "dcs_20";
		apple,always-on;
		power-domains = <&ps_amcc20>;
	};

	ps_dcs_21: power-controller@4d8 {
		compatible = "apple,t6050-pmgr-pwrstate", "apple,t8103-pmgr-pwrstate";
		reg = <0x4d8 4>;
		#power-domain-cells = <0>;
		#reset-cells = <0>;
		label = "dcs_21";
		apple,always-on;
		power-domains = <&ps_amcc21>;
	};

	ps_dcs_22: power-controller@4e8 {
		compatible = "apple,t6050-pmgr-pwrstate", "apple,t8103-pmgr-pwrstate";
		reg = <0x4e8 4>;
		#power-domain-cells = <0>;
		#reset-cells = <0>;
		label = "dcs_22";
		apple,always-on;
		power-domains = <&ps_amcc22>;
	};

	ps_dcs_23: power-controller@4f8 {
		compatible = "apple,t6050-pmgr-pwrstate", "apple,t8103-pmgr-pwrstate";
		reg = <0x4f8 4>;
		#power-domain-cells = <0>;
		#reset-cells = <0>;
		label = "dcs_23";
		apple,always-on;
		power-domains = <&ps_amcc23>;
	};

	ps_fab_afc_amcc_5: power-controller@508 {
		compatible = "apple,t6050-pmgr-pwrstate", "apple,t8103-pmgr-pwrstate";
		reg = <0x508 4>;
		#power-domain-cells = <0>;
		#reset-cells = <0>;
		label = "fab_afc_amcc_5";
		apple,always-on;
	};

	ps_fab_afi_amcc_6: power-controller@510 {
		compatible = "apple,t6050-pmgr-pwrstate", "apple,t8103-pmgr-pwrstate";
		reg = <0x510 4>;
		#power-domain-cells = <0>;
		#reset-cells = <0>;
		label = "fab_afi_amcc_6";
		apple,always-on;
	};

	ps_amcc24: power-controller@518 {
		compatible = "apple,t6050-pmgr-pwrstate", "apple,t8103-pmgr-pwrstate";
		reg = <0x518 4>;
		#power-domain-cells = <0>;
		#reset-cells = <0>;
		label = "amcc24";
		apple,always-on;
		power-domains = <&ps_fab_afi_amcc_6>;
	};

	ps_amcc25: power-controller@520 {
		compatible = "apple,t6050-pmgr-pwrstate", "apple,t8103-pmgr-pwrstate";
		reg = <0x520 4>;
		#power-domain-cells = <0>;
		#reset-cells = <0>;
		label = "amcc25";
		apple,always-on;
		power-domains = <&ps_fab_afi_amcc_6>;
	};

	ps_amcc26: power-controller@528 {
		compatible = "apple,t6050-pmgr-pwrstate", "apple,t8103-pmgr-pwrstate";
		reg = <0x528 4>;
		#power-domain-cells = <0>;
		#reset-cells = <0>;
		label = "amcc26";
		apple,always-on;
		power-domains = <&ps_fab_afi_amcc_6>;
	};

	ps_amcc27: power-controller@530 {
		compatible = "apple,t6050-pmgr-pwrstate", "apple,t8103-pmgr-pwrstate";
		reg = <0x530 4>;
		#power-domain-cells = <0>;
		#reset-cells = <0>;
		label = "amcc27";
		apple,always-on;
		power-domains = <&ps_fab_afi_amcc_6>;
	};

	ps_fab_afr_amcc_12: power-controller@538 {
		compatible = "apple,t6050-pmgr-pwrstate", "apple,t8103-pmgr-pwrstate";
		reg = <0x538 4>;
		#power-domain-cells = <0>;
		#reset-cells = <0>;
		label = "fab_afr_amcc_12";
		apple,always-on;
		power-domains = <&ps_fab_afi_amcc_6>;
	};

	ps_fab_afr_amcc_13: power-controller@540 {
		compatible = "apple,t6050-pmgr-pwrstate", "apple,t8103-pmgr-pwrstate";
		reg = <0x540 4>;
		#power-domain-cells = <0>;
		#reset-cells = <0>;
		label = "fab_afr_amcc_13";
		apple,always-on;
		power-domains = <&ps_fab_afi_amcc_6>;
	};

	ps_dcs_24: power-controller@548 {
		compatible = "apple,t6050-pmgr-pwrstate", "apple,t8103-pmgr-pwrstate";
		reg = <0x548 4>;
		#power-domain-cells = <0>;
		#reset-cells = <0>;
		label = "dcs_24";
		apple,always-on;
		power-domains = <&ps_amcc24>;
	};

	ps_dcs_25: power-controller@558 {
		compatible = "apple,t6050-pmgr-pwrstate", "apple,t8103-pmgr-pwrstate";
		reg = <0x558 4>;
		#power-domain-cells = <0>;
		#reset-cells = <0>;
		label = "dcs_25";
		apple,always-on;
		power-domains = <&ps_amcc25>;
	};

	ps_dcs_26: power-controller@568 {
		compatible = "apple,t6050-pmgr-pwrstate", "apple,t8103-pmgr-pwrstate";
		reg = <0x568 4>;
		#power-domain-cells = <0>;
		#reset-cells = <0>;
		label = "dcs_26";
		apple,always-on;
		power-domains = <&ps_amcc26>;
	};

	ps_dcs_27: power-controller@578 {
		compatible = "apple,t6050-pmgr-pwrstate", "apple,t8103-pmgr-pwrstate";
		reg = <0x578 4>;
		#power-domain-cells = <0>;
		#reset-cells = <0>;
		label = "dcs_27";
		apple,always-on;
		power-domains = <&ps_amcc27>;
	};

	ps_fab_afc_amcc_6: power-controller@588 {
		compatible = "apple,t6050-pmgr-pwrstate", "apple,t8103-pmgr-pwrstate";
		reg = <0x588 4>;
		#power-domain-cells = <0>;
		#reset-cells = <0>;
		label = "fab_afc_amcc_6";
		apple,always-on;
	};

	ps_fab_afi_amcc_7: power-controller@590 {
		compatible = "apple,t6050-pmgr-pwrstate", "apple,t8103-pmgr-pwrstate";
		reg = <0x590 4>;
		#power-domain-cells = <0>;
		#reset-cells = <0>;
		label = "fab_afi_amcc_7";
		apple,always-on;
	};

	ps_amcc28: power-controller@598 {
		compatible = "apple,t6050-pmgr-pwrstate", "apple,t8103-pmgr-pwrstate";
		reg = <0x598 4>;
		#power-domain-cells = <0>;
		#reset-cells = <0>;
		label = "amcc28";
		apple,always-on;
		power-domains = <&ps_fab_afi_amcc_7>;
	};

	ps_amcc29: power-controller@5a0 {
		compatible = "apple,t6050-pmgr-pwrstate", "apple,t8103-pmgr-pwrstate";
		reg = <0x5a0 4>;
		#power-domain-cells = <0>;
		#reset-cells = <0>;
		label = "amcc29";
		apple,always-on;
		power-domains = <&ps_fab_afi_amcc_7>;
	};

	ps_amcc30: power-controller@5a8 {
		compatible = "apple,t6050-pmgr-pwrstate", "apple,t8103-pmgr-pwrstate";
		reg = <0x5a8 4>;
		#power-domain-cells = <0>;
		#reset-cells = <0>;
		label = "amcc30";
		apple,always-on;
		power-domains = <&ps_fab_afi_amcc_7>;
	};

	ps_amcc31: power-controller@5b0 {
		compatible = "apple,t6050-pmgr-pwrstate", "apple,t8103-pmgr-pwrstate";
		reg = <0x5b0 4>;
		#power-domain-cells = <0>;
		#reset-cells = <0>;
		label = "amcc31";
		apple,always-on;
		power-domains = <&ps_fab_afi_amcc_7>;
	};

	ps_fab_afr_amcc_14: power-controller@5b8 {
		compatible = "apple,t6050-pmgr-pwrstate", "apple,t8103-pmgr-pwrstate";
		reg = <0x5b8 4>;
		#power-domain-cells = <0>;
		#reset-cells = <0>;
		label = "fab_afr_amcc_14";
		apple,always-on;
		power-domains = <&ps_fab_afi_amcc_7>;
	};

	ps_fab_afr_amcc_15: power-controller@5c0 {
		compatible = "apple,t6050-pmgr-pwrstate", "apple,t8103-pmgr-pwrstate";
		reg = <0x5c0 4>;
		#power-domain-cells = <0>;
		#reset-cells = <0>;
		label = "fab_afr_amcc_15";
		apple,always-on;
		power-domains = <&ps_fab_afi_amcc_7>;
	};

	ps_dcs_28: power-controller@5d0 {
		compatible = "apple,t6050-pmgr-pwrstate", "apple,t8103-pmgr-pwrstate";
		reg = <0x5d0 4>;
		#power-domain-cells = <0>;
		#reset-cells = <0>;
		label = "dcs_28";
		apple,always-on;
		power-domains = <&ps_amcc28>;
	};

	ps_dcs_29: power-controller@5e0 {
		compatible = "apple,t6050-pmgr-pwrstate", "apple,t8103-pmgr-pwrstate";
		reg = <0x5e0 4>;
		#power-domain-cells = <0>;
		#reset-cells = <0>;
		label = "dcs_29";
		apple,always-on;
		power-domains = <&ps_amcc29>;
	};

	ps_dcs_30: power-controller@5f0 {
		compatible = "apple,t6050-pmgr-pwrstate", "apple,t8103-pmgr-pwrstate";
		reg = <0x5f0 4>;
		#power-domain-cells = <0>;
		#reset-cells = <0>;
		label = "dcs_30";
		apple,always-on;
		power-domains = <&ps_amcc30>;
	};

	ps_dcs_31: power-controller@600 {
		compatible = "apple,t6050-pmgr-pwrstate", "apple,t8103-pmgr-pwrstate";
		reg = <0x600 4>;
		#power-domain-cells = <0>;
		#reset-cells = <0>;
		label = "dcs_31";
		apple,always-on;
		power-domains = <&ps_amcc31>;
	};

	ps_fab_afc_amcc_7: power-controller@610 {
		compatible = "apple,t6050-pmgr-pwrstate", "apple,t8103-pmgr-pwrstate";
		reg = <0x610 4>;
		#power-domain-cells = <0>;
		#reset-cells = <0>;
		label = "fab_afc_amcc_7";
		apple,always-on;
	};

	ps_fab_b2bd_afi_0: power-controller@618 {
		compatible = "apple,t6050-pmgr-pwrstate", "apple,t8103-pmgr-pwrstate";
		reg = <0x618 4>;
		#power-domain-cells = <0>;
		#reset-cells = <0>;
		label = "fab_b2bd_afi_0";
		apple,always-on;
	};

	ps_fab_b2bd_afi_1: power-controller@620 {
		compatible = "apple,t6050-pmgr-pwrstate", "apple,t8103-pmgr-pwrstate";
		reg = <0x620 4>;
		#power-domain-cells = <0>;
		#reset-cells = <0>;
		label = "fab_b2bd_afi_1";
		apple,always-on;
	};

	ps_b2bd_afi_0: power-controller@628 {
		compatible = "apple,t6050-pmgr-pwrstate", "apple,t8103-pmgr-pwrstate";
		reg = <0x628 4>;
		#power-domain-cells = <0>;
		#reset-cells = <0>;
		label = "b2bd_afi_0";
		apple,always-on;
	};

	ps_b2bd_afi_0_dfx: power-controller@630 {
		compatible = "apple,t6050-pmgr-pwrstate", "apple,t8103-pmgr-pwrstate";
		reg = <0x630 4>;
		#power-domain-cells = <0>;
		#reset-cells = <0>;
		label = "b2bd_afi_0_dfx";
		apple,always-on;
		power-domains = <&ps_b2bd_afi_0>;
	};

	ps_b2bd_afi_1: power-controller@638 {
		compatible = "apple,t6050-pmgr-pwrstate", "apple,t8103-pmgr-pwrstate";
		reg = <0x638 4>;
		#power-domain-cells = <0>;
		#reset-cells = <0>;
		label = "b2bd_afi_1";
		apple,always-on;
	};

	ps_b2bd_afi_1_dfx: power-controller@640 {
		compatible = "apple,t6050-pmgr-pwrstate", "apple,t8103-pmgr-pwrstate";
		reg = <0x640 4>;
		#power-domain-cells = <0>;
		#reset-cells = <0>;
		label = "b2bd_afi_1_dfx";
		apple,always-on;
		power-domains = <&ps_b2bd_afi_1>;
	};

	ps_fab_b2bd_afc_0: power-controller@648 {
		compatible = "apple,t6050-pmgr-pwrstate", "apple,t8103-pmgr-pwrstate";
		reg = <0x648 4>;
		#power-domain-cells = <0>;
		#reset-cells = <0>;
		label = "fab_b2bd_afc_0";
		apple,always-on;
	};

	ps_fab_b2bd_afc_1: power-controller@650 {
		compatible = "apple,t6050-pmgr-pwrstate", "apple,t8103-pmgr-pwrstate";
		reg = <0x650 4>;
		#power-domain-cells = <0>;
		#reset-cells = <0>;
		label = "fab_b2bd_afc_1";
		apple,always-on;
	};

	ps_b2bd_afc_0: power-controller@658 {
		compatible = "apple,t6050-pmgr-pwrstate", "apple,t8103-pmgr-pwrstate";
		reg = <0x658 4>;
		#power-domain-cells = <0>;
		#reset-cells = <0>;
		label = "b2bd_afc_0";
		apple,always-on;
	};

	ps_b2bd_afc_0_dfx: power-controller@660 {
		compatible = "apple,t6050-pmgr-pwrstate", "apple,t8103-pmgr-pwrstate";
		reg = <0x660 4>;
		#power-domain-cells = <0>;
		#reset-cells = <0>;
		label = "b2bd_afc_0_dfx";
		apple,always-on;
		power-domains = <&ps_b2bd_afc_0>;
	};

	ps_b2bd_afc_1: power-controller@668 {
		compatible = "apple,t6050-pmgr-pwrstate", "apple,t8103-pmgr-pwrstate";
		reg = <0x668 4>;
		#power-domain-cells = <0>;
		#reset-cells = <0>;
		label = "b2bd_afc_1";
		apple,always-on;
	};

	ps_b2bd_afc_1_dfx: power-controller@670 {
		compatible = "apple,t6050-pmgr-pwrstate", "apple,t8103-pmgr-pwrstate";
		reg = <0x670 4>;
		#power-domain-cells = <0>;
		#reset-cells = <0>;
		label = "b2bd_afc_1_dfx";
		apple,always-on;
		power-domains = <&ps_b2bd_afc_1>;
	};

	ps_b2bd_afr_0: power-controller@678 {
		compatible = "apple,t6050-pmgr-pwrstate", "apple,t8103-pmgr-pwrstate";
		reg = <0x678 4>;
		#power-domain-cells = <0>;
		#reset-cells = <0>;
		label = "b2bd_afr_0";
		apple,always-on;
	};

	ps_b2bd_afr_1: power-controller@680 {
		compatible = "apple,t6050-pmgr-pwrstate", "apple,t8103-pmgr-pwrstate";
		reg = <0x680 4>;
		#power-domain-cells = <0>;
		#reset-cells = <0>;
		label = "b2bd_afr_1";
		apple,always-on;
		power-domains = <&ps_b2bd_afr_0>;
	};

	ps_b2bd_afr_dfx_0: power-controller@688 {
		compatible = "apple,t6050-pmgr-pwrstate", "apple,t8103-pmgr-pwrstate";
		reg = <0x688 4>;
		#power-domain-cells = <0>;
		#reset-cells = <0>;
		label = "b2bd_afr_dfx_0";
		apple,always-on;
		power-domains = <&ps_b2bd_afr_0>;
	};

	ps_b2bd_afr_dfx_1: power-controller@690 {
		compatible = "apple,t6050-pmgr-pwrstate", "apple,t8103-pmgr-pwrstate";
		reg = <0x690 4>;
		#power-domain-cells = <0>;
		#reset-cells = <0>;
		label = "b2bd_afr_dfx_1";
		apple,always-on;
		power-domains = <&ps_b2bd_afr_1>;
	};

	ps_b2bd_afr_3: power-controller@698 {
		compatible = "apple,t6050-pmgr-pwrstate", "apple,t8103-pmgr-pwrstate";
		reg = <0x698 4>;
		#power-domain-cells = <0>;
		#reset-cells = <0>;
		label = "b2bd_afr_3";
		apple,always-on;
	};

	ps_b2bd_afr_2: power-controller@6a0 {
		compatible = "apple,t6050-pmgr-pwrstate", "apple,t8103-pmgr-pwrstate";
		reg = <0x6a0 4>;
		#power-domain-cells = <0>;
		#reset-cells = <0>;
		label = "b2bd_afr_2";
		apple,always-on;
		power-domains = <&ps_b2bd_afr_3>;
	};

	ps_b2bd_afr_dfx_3: power-controller@6a8 {
		compatible = "apple,t6050-pmgr-pwrstate", "apple,t8103-pmgr-pwrstate";
		reg = <0x6a8 4>;
		#power-domain-cells = <0>;
		#reset-cells = <0>;
		label = "b2bd_afr_dfx_3";
		apple,always-on;
		power-domains = <&ps_b2bd_afr_3>;
	};

	ps_b2bd_afr_dfx_2: power-controller@6b0 {
		compatible = "apple,t6050-pmgr-pwrstate", "apple,t8103-pmgr-pwrstate";
		reg = <0x6b0 4>;
		#power-domain-cells = <0>;
		#reset-cells = <0>;
		label = "b2bd_afr_dfx_2";
		apple,always-on;
		power-domains = <&ps_b2bd_afr_2>;
	};

	ps_b2bg_dft: power-controller@6b8 {
		compatible = "apple,t6050-pmgr-pwrstate", "apple,t8103-pmgr-pwrstate";
		reg = <0x6b8 4>;
		#power-domain-cells = <0>;
		#reset-cells = <0>;
		label = "b2bg_dft";
	};

	ps_b2bg_cntl_dfx: power-controller@6c0 {
		compatible = "apple,t6050-pmgr-pwrstate", "apple,t8103-pmgr-pwrstate";
		reg = <0x6c0 4>;
		#power-domain-cells = <0>;
		#reset-cells = <0>;
		label = "b2bg_cntl_dfx";
	};

	ps_b2bg_dbg_0: power-controller@6c8 {
		compatible = "apple,t6050-pmgr-pwrstate", "apple,t8103-pmgr-pwrstate";
		reg = <0x6c8 4>;
		#power-domain-cells = <0>;
		#reset-cells = <0>;
		label = "b2bg_dbg_0";
	};

	ps_b2bg_dbg_1: power-controller@6d0 {
		compatible = "apple,t6050-pmgr-pwrstate", "apple,t8103-pmgr-pwrstate";
		reg = <0x6d0 4>;
		#power-domain-cells = <0>;
		#reset-cells = <0>;
		label = "b2bg_dbg_1";
	};

	ps_b2bg_dbg_2: power-controller@6d8 {
		compatible = "apple,t6050-pmgr-pwrstate", "apple,t8103-pmgr-pwrstate";
		reg = <0x6d8 4>;
		#power-domain-cells = <0>;
		#reset-cells = <0>;
		label = "b2bg_dbg_2";
	};

	ps_b2bd_cntl_dfx_0: power-controller@6e0 {
		compatible = "apple,t6050-pmgr-pwrstate", "apple,t8103-pmgr-pwrstate";
		reg = <0x6e0 4>;
		#power-domain-cells = <0>;
		#reset-cells = <0>;
		label = "b2bd_cntl_dfx_0";
	};

	ps_b2bd_cntl_dfx_1: power-controller@6e8 {
		compatible = "apple,t6050-pmgr-pwrstate", "apple,t8103-pmgr-pwrstate";
		reg = <0x6e8 4>;
		#power-domain-cells = <0>;
		#reset-cells = <0>;
		label = "b2bd_cntl_dfx_1";
	};

	ps_b2bd_dbg_0: power-controller@6f0 {
		compatible = "apple,t6050-pmgr-pwrstate", "apple,t8103-pmgr-pwrstate";
		reg = <0x6f0 4>;
		#power-domain-cells = <0>;
		#reset-cells = <0>;
		label = "b2bd_dbg_0";
	};

	ps_b2bd_dbg_1: power-controller@6f8 {
		compatible = "apple,t6050-pmgr-pwrstate", "apple,t8103-pmgr-pwrstate";
		reg = <0x6f8 4>;
		#power-domain-cells = <0>;
		#reset-cells = <0>;
		label = "b2bd_dbg_1";
	};

	ps_b2bd_dbg_2: power-controller@700 {
		compatible = "apple,t6050-pmgr-pwrstate", "apple,t8103-pmgr-pwrstate";
		reg = <0x700 4>;
		#power-domain-cells = <0>;
		#reset-cells = <0>;
		label = "b2bd_dbg_2";
	};

	ps_b2bd_dbg_3: power-controller@708 {
		compatible = "apple,t6050-pmgr-pwrstate", "apple,t8103-pmgr-pwrstate";
		reg = <0x708 4>;
		#power-domain-cells = <0>;
		#reset-cells = <0>;
		label = "b2bd_dbg_3";
	};

	ps_b2bd_dbg_4: power-controller@710 {
		compatible = "apple,t6050-pmgr-pwrstate", "apple,t8103-pmgr-pwrstate";
		reg = <0x710 4>;
		#power-domain-cells = <0>;
		#reset-cells = <0>;
		label = "b2bd_dbg_4";
	};

	ps_venc0_dma: power-controller@8000 {
		compatible = "apple,t6050-pmgr-pwrstate", "apple,t8103-pmgr-pwrstate";
		reg = <0x8000 4>;
		#power-domain-cells = <0>;
		#reset-cells = <0>;
		label = "venc0_dma";
		power-domains = <&ps_venc0_sys>;
	};

	ps_venc0_pipe4: power-controller@8008 {
		compatible = "apple,t6050-pmgr-pwrstate", "apple,t8103-pmgr-pwrstate";
		reg = <0x8008 4>;
		#power-domain-cells = <0>;
		#reset-cells = <0>;
		label = "venc0_pipe4";
		power-domains = <&ps_venc0_dma>;
	};

	ps_venc0_pipe5: power-controller@8010 {
		compatible = "apple,t6050-pmgr-pwrstate", "apple,t8103-pmgr-pwrstate";
		reg = <0x8010 4>;
		#power-domain-cells = <0>;
		#reset-cells = <0>;
		label = "venc0_pipe5";
		power-domains = <&ps_venc0_dma>;
	};

	ps_venc0_me0: power-controller@8018 {
		compatible = "apple,t6050-pmgr-pwrstate", "apple,t8103-pmgr-pwrstate";
		reg = <0x8018 4>;
		#power-domain-cells = <0>;
		#reset-cells = <0>;
		label = "venc0_me0";
		power-domains = <&ps_venc0_dma>;
	};

	ps_venc0_me1: power-controller@8020 {
		compatible = "apple,t6050-pmgr-pwrstate", "apple,t8103-pmgr-pwrstate";
		reg = <0x8020 4>;
		#power-domain-cells = <0>;
		#reset-cells = <0>;
		label = "venc0_me1";
		power-domains = <&ps_venc0_me0>;
	};

	ps_venc1_dma: power-controller@8028 {
		compatible = "apple,t6050-pmgr-pwrstate", "apple,t8103-pmgr-pwrstate";
		reg = <0x8028 4>;
		#power-domain-cells = <0>;
		#reset-cells = <0>;
		label = "venc1_dma";
		power-domains = <&ps_venc1_sys>;
	};

	ps_venc1_pipe4: power-controller@8030 {
		compatible = "apple,t6050-pmgr-pwrstate", "apple,t8103-pmgr-pwrstate";
		reg = <0x8030 4>;
		#power-domain-cells = <0>;
		#reset-cells = <0>;
		label = "venc1_pipe4";
		power-domains = <&ps_venc1_dma>;
	};

	ps_venc1_pipe5: power-controller@8038 {
		compatible = "apple,t6050-pmgr-pwrstate", "apple,t8103-pmgr-pwrstate";
		reg = <0x8038 4>;
		#power-domain-cells = <0>;
		#reset-cells = <0>;
		label = "venc1_pipe5";
		power-domains = <&ps_venc1_dma>;
	};

	ps_venc1_me0: power-controller@8040 {
		compatible = "apple,t6050-pmgr-pwrstate", "apple,t8103-pmgr-pwrstate";
		reg = <0x8040 4>;
		#power-domain-cells = <0>;
		#reset-cells = <0>;
		label = "venc1_me0";
		power-domains = <&ps_venc1_dma>;
	};

	ps_venc1_me1: power-controller@8048 {
		compatible = "apple,t6050-pmgr-pwrstate", "apple,t8103-pmgr-pwrstate";
		reg = <0x8048 4>;
		#power-domain-cells = <0>;
		#reset-cells = <0>;
		label = "venc1_me1";
		power-domains = <&ps_venc1_me0>;
	};
};

&pmgr5 {

	ps_debug_gfx_gated: power-controller@58 {
		compatible = "apple,t6050-pmgr-pwrstate", "apple,t8103-pmgr-pwrstate";
		reg = <0x58 4>;
		#power-domain-cells = <0>;
		#reset-cells = <0>;
		label = "debug_gfx_gated";
		apple,always-on;
	};

	ps_nub_gfx_aon: power-controller@60 {
		compatible = "apple,t6050-pmgr-pwrstate", "apple,t8103-pmgr-pwrstate";
		reg = <0x60 4>;
		#power-domain-cells = <0>;
		#reset-cells = <0>;
		label = "nub_gfx_aon";
		apple,always-on;
	};

	ps_nub_gfx_gpio: power-controller@68 {
		compatible = "apple,t6050-pmgr-pwrstate", "apple,t8103-pmgr-pwrstate";
		reg = <0x68 4>;
		#power-domain-cells = <0>;
		#reset-cells = <0>;
		label = "nub_gfx_gpio";
		apple,always-on;
	};

	ps_nub_gfx_fabric: power-controller@78 {
		compatible = "apple,t6050-pmgr-pwrstate", "apple,t8103-pmgr-pwrstate";
		reg = <0x78 4>;
		#power-domain-cells = <0>;
		#reset-cells = <0>;
		label = "nub_gfx_fabric";
		apple,always-on;
	};

	ps_debug_gfx_switch: power-controller@80 {
		compatible = "apple,t6050-pmgr-pwrstate", "apple,t8103-pmgr-pwrstate";
		reg = <0x80 4>;
		#power-domain-cells = <0>;
		#reset-cells = <0>;
		label = "debug_gfx_switch";
		apple,always-on;
	};

	ps_nub_gfx_sram: power-controller@4000 {
		compatible = "apple,t6050-pmgr-pwrstate", "apple,t8103-pmgr-pwrstate";
		reg = <0x4000 4>;
		#power-domain-cells = <0>;
		#reset-cells = <0>;
		label = "nub_gfx_sram";
		apple,always-on;
		power-domains = <&ps_nub_gfx_fabric>;
	};
};

